AUTOSAR XML (schema 3.1.2)
package /Components/SWC_InMdlT
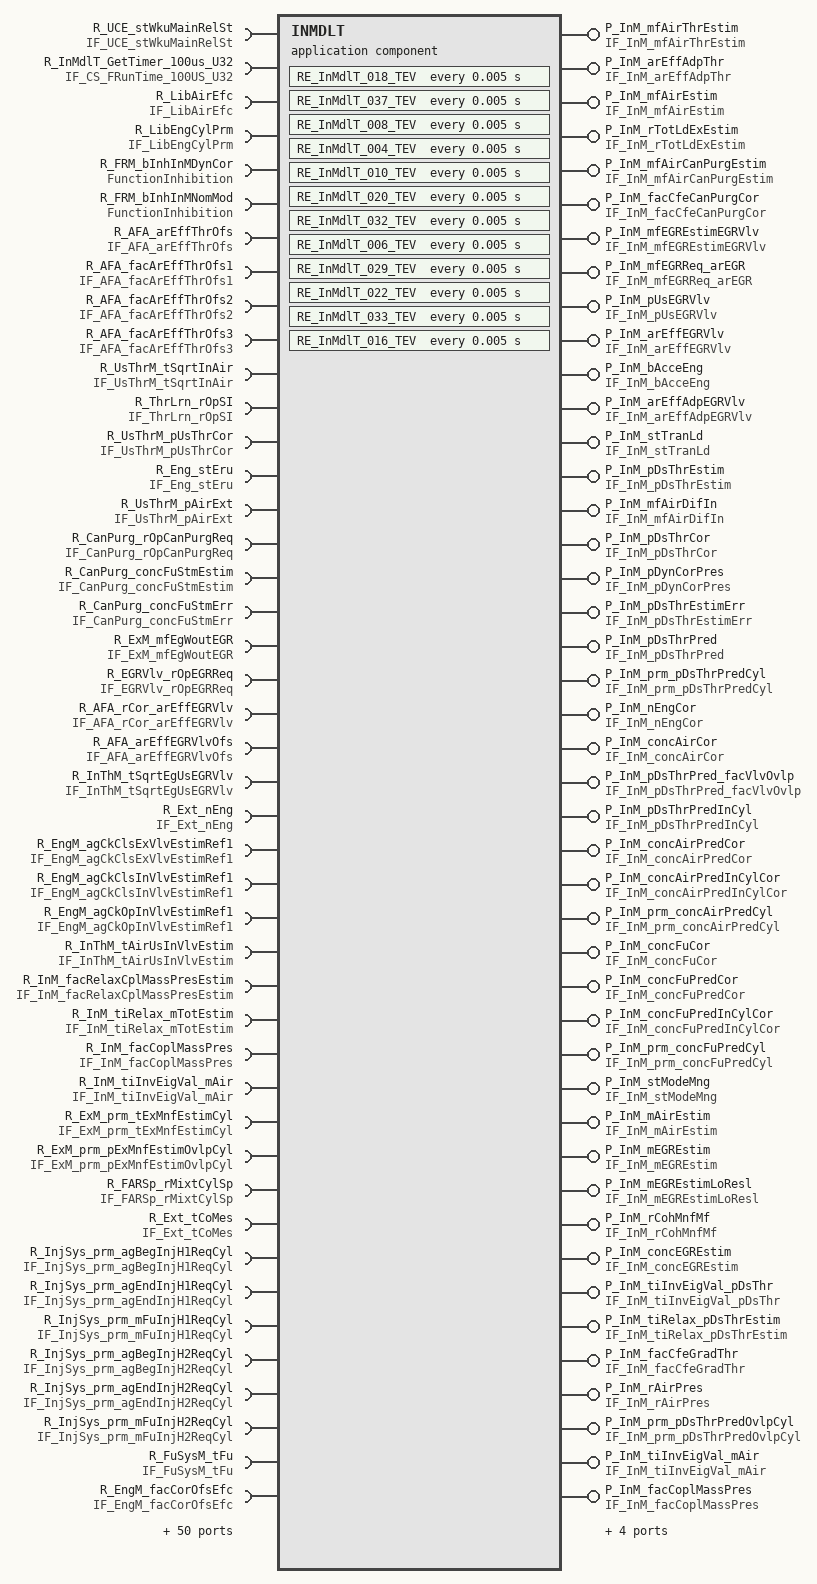
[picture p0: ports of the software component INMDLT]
  application software component type INMDLT  # InMdlT
    6 x require port:
      R_UCE_stWkuMainRelSt: required-interface=IF_UCE_stWkuMainRelSt
      R_InMdlT_GetTimer_100us_U32: required-interface=IF_CS_FRunTime_100US_U32
      R_LibAirEfc: required-interface=IF_LibAirEfc
      R_LibEngCylPrm: required-interface=IF_LibEngCylPrm
      R_FRM_bInhInMDynCor: required-interface=FunctionInhibition
      R_FRM_bInhInMNomMod: required-interface=FunctionInhibition
    48 x provide port:
      P_InM_mfAirThrEstim: unqueued-sender-com-spec{data-element=InM_mfAirThrEstim, can-invalidate=false, init-value=ConstantValue}, provided-interface=IF_InM_mfAirThrEstim
      P_InM_arEffAdpThr: unqueued-sender-com-spec{data-element=InM_arEffAdpThr, can-invalidate=false, init-value=ConstantValue1}, provided-interface=IF_InM_arEffAdpThr
      P_InM_mfAirEstim: unqueued-sender-com-spec{data-element=InM_mfAirEstim, can-invalidate=false, init-value=UInt16InitValue}, provided-interface=IF_InM_mfAirEstim
      P_InM_rTotLdExEstim: unqueued-sender-com-spec{data-element=InM_rTotLdExEstim, can-invalidate=false, init-value=UInt16InitValue3}, provided-interface=IF_InM_rTotLdExEstim
      P_InM_mfAirCanPurgEstim: unqueued-sender-com-spec{data-element=InM_mfAirCanPurgEstim, can-invalidate=false, init-value=ConstantValue5}, provided-interface=IF_InM_mfAirCanPurgEstim
      P_InM_facCfeCanPurgCor: unqueued-sender-com-spec{data-element=InM_facCfeCanPurgCor, can-invalidate=false, init-value=UInt8InitValue}, provided-interface=IF_InM_facCfeCanPurgCor
      P_InM_mfEGREstimEGRVlv: unqueued-sender-com-spec{data-element=InM_mfEGREstimEGRVlv, can-invalidate=false, init-value=ConstantValue7}, provided-interface=IF_InM_mfEGREstimEGRVlv
      P_InM_mfEGRReq_arEGR: unqueued-sender-com-spec{data-element=InM_mfEGRReq_arEGR, can-invalidate=false, init-value=UInt16InitValue9}, provided-interface=IF_InM_mfEGRReq_arEGR
      P_InM_pUsEGRVlv: unqueued-sender-com-spec{data-element=InM_pUsEGRVlv, can-invalidate=false, init-value=UInt16InitValue11}, provided-interface=IF_InM_pUsEGRVlv
      P_InM_arEffEGRVlv: unqueued-sender-com-spec{data-element=InM_arEffEGRVlv, can-invalidate=false, init-value=ConstantValue13}, provided-interface=IF_InM_arEffEGRVlv
      P_InM_bAcceEng: unqueued-sender-com-spec{data-element=InM_bAcceEng, can-invalidate=false, init-value=BooleanInitValue}, provided-interface=IF_InM_bAcceEng
      P_InM_arEffAdpEGRVlv: unqueued-sender-com-spec{data-element=InM_arEffAdpEGRVlv, can-invalidate=false, init-value=ConstantValue15}, provided-interface=IF_InM_arEffAdpEGRVlv
      P_InM_stTranLd: unqueued-sender-com-spec{data-element=InM_stTranLd, can-invalidate=false, init-value=UInt8InitValue17}, provided-interface=IF_InM_stTranLd
      P_InM_pDsThrEstim: unqueued-sender-com-spec{data-element=InM_pDsThrEstim, can-invalidate=false, init-value=ConstantValue19}, provided-interface=IF_InM_pDsThrEstim
      P_InM_mfAirDifIn: unqueued-sender-com-spec{data-element=InM_mfAirDifIn, can-invalidate=false, init-value=SInt16InitValue}, provided-interface=IF_InM_mfAirDifIn
      P_InM_pDsThrCor: unqueued-sender-com-spec{data-element=InM_pDsThrCor, can-invalidate=false, init-value=ConstantValue21}, provided-interface=IF_InM_pDsThrCor
      P_InM_pDynCorPres: unqueued-sender-com-spec{data-element=InM_pDynCorPres, can-invalidate=false, init-value=ConstantValue23}, provided-interface=IF_InM_pDynCorPres
      P_InM_pDsThrEstimErr: unqueued-sender-com-spec{data-element=InM_pDsThrEstimErr, can-invalidate=false, init-value=ConstantValue25}, provided-interface=IF_InM_pDsThrEstimErr
      P_InM_pDsThrPred: unqueued-sender-com-spec{data-element=InM_pDsThrPred, can-invalidate=false, init-value=ConstantValue27}, provided-interface=IF_InM_pDsThrPred
      P_InM_prm_pDsThrPredCyl: unqueued-sender-com-spec{data-element=InM_prm_pDsThrPredCyl, can-invalidate=false, init-value=ArrayConstantValue}, provided-interface=IF_InM_prm_pDsThrPredCyl
      P_InM_nEngCor: unqueued-sender-com-spec{data-element=InM_nEngCor, can-invalidate=false, init-value=UInt16InitValue29}, provided-interface=IF_InM_nEngCor
      P_InM_concAirCor: unqueued-sender-com-spec{data-element=InM_concAirCor, can-invalidate=false, init-value=ConstantValue31}, provided-interface=IF_InM_concAirCor
      P_InM_pDsThrPred_facVlvOvlp: unqueued-sender-com-spec{data-element=InM_pDsThrPred_facVlvOvlp, can-invalidate=false, init-value=ConstantValue33}, provided-interface=IF_InM_pDsThrPred_facVlvOvlp
      P_InM_pDsThrPredInCyl: unqueued-sender-com-spec{data-element=InM_pDsThrPredInCyl, can-invalidate=false, init-value=UInt16InitValue35}, provided-interface=IF_InM_pDsThrPredInCyl
      P_InM_concAirPredCor: unqueued-sender-com-spec{data-element=InM_concAirPredCor, can-invalidate=false, init-value=UInt16InitValue37}, provided-interface=IF_InM_concAirPredCor
      P_InM_concAirPredInCylCor: unqueued-sender-com-spec{data-element=InM_concAirPredInCylCor, can-invalidate=false, init-value=UInt16InitValue39}, provided-interface=IF_InM_concAirPredInCylCor
      P_InM_prm_concAirPredCyl: unqueued-sender-com-spec{data-element=InM_prm_concAirPredCyl, can-invalidate=false, init-value=ArrayConstantValue41}, provided-interface=IF_InM_prm_concAirPredCyl
      P_InM_concFuCor: unqueued-sender-com-spec{data-element=InM_concFuCor, can-invalidate=false, init-value=UInt16InitValue43}, provided-interface=IF_InM_concFuCor
      P_InM_concFuPredCor: unqueued-sender-com-spec{data-element=InM_concFuPredCor, can-invalidate=false, init-value=UInt16InitValue45}, provided-interface=IF_InM_concFuPredCor
      P_InM_concFuPredInCylCor: unqueued-sender-com-spec{data-element=InM_concFuPredInCylCor, can-invalidate=false, init-value=UInt16InitValue47}, provided-interface=IF_InM_concFuPredInCylCor
      P_InM_prm_concFuPredCyl: unqueued-sender-com-spec{data-element=InM_prm_concFuPredCyl, can-invalidate=false, init-value=rt_Array_UInt16_6InitValue}, provided-interface=IF_InM_prm_concFuPredCyl
      P_InM_stModeMng: unqueued-sender-com-spec{data-element=InM_stModeMng, can-invalidate=false, init-value=UInt8InitValue49}, provided-interface=IF_InM_stModeMng
      P_InM_mAirEstim: unqueued-sender-com-spec{data-element=InM_mAirEstim, can-invalidate=false, init-value=UInt32InitValue}, provided-interface=IF_InM_mAirEstim
      P_InM_mEGREstim: unqueued-sender-com-spec{data-element=InM_mEGREstim, can-invalidate=false, init-value=ConstantValue51}, provided-interface=IF_InM_mEGREstim
      P_InM_mEGREstimLoResl: unqueued-sender-com-spec{data-element=InM_mEGREstimLoResl, can-invalidate=false, init-value=UInt16InitValue53}, provided-interface=IF_InM_mEGREstimLoResl
      P_InM_rCohMnfMf: unqueued-sender-com-spec{data-element=InM_rCohMnfMf, can-invalidate=false, init-value=UInt16InitValue55}, provided-interface=IF_InM_rCohMnfMf
      P_InM_concEGREstim: unqueued-sender-com-spec{data-element=InM_concEGREstim, can-invalidate=false, init-value=ConstantValue57}, provided-interface=IF_InM_concEGREstim
      P_InM_tiInvEigVal_pDsThr: unqueued-sender-com-spec{data-element=InM_tiInvEigVal_pDsThr, can-invalidate=false, init-value=UInt16InitValue59}, provided-interface=IF_InM_tiInvEigVal_pDsThr
      P_InM_tiRelax_pDsThrEstim: unqueued-sender-com-spec{data-element=InM_tiRelax_pDsThrEstim, can-invalidate=false, init-value=UInt8InitValue61}, provided-interface=IF_InM_tiRelax_pDsThrEstim
      P_InM_facCfeGradThr: unqueued-sender-com-spec{data-element=InM_facCfeGradThr, can-invalidate=false, init-value=UInt16InitValue63}, provided-interface=IF_InM_facCfeGradThr
      P_InM_rAirPres: unqueued-sender-com-spec{data-element=InM_rAirPres, can-invalidate=false, init-value=ConstantValue65}, provided-interface=IF_InM_rAirPres
      P_InM_prm_pDsThrPredOvlpCyl: unqueued-sender-com-spec{data-element=InM_prm_pDsThrPredOvlpCyl, can-invalidate=false, init-value=ArrayConstantValue67}, provided-interface=IF_InM_prm_pDsThrPredOvlpCyl
      P_InM_tiInvEigVal_mAir: unqueued-sender-com-spec{data-element=InM_tiInvEigVal_mAir, can-invalidate=false, init-value=UInt16InitValue69}, provided-interface=IF_InM_tiInvEigVal_mAir
      P_InM_facCoplMassPres: unqueued-sender-com-spec{data-element=InM_facCoplMassPres, can-invalidate=false, init-value=UInt16InitValue71}, provided-interface=IF_InM_facCoplMassPres
      P_InM_tiRelax_mTotEstim: unqueued-sender-com-spec{data-element=InM_tiRelax_mTotEstim, can-invalidate=false, init-value=UInt8InitValue73}, provided-interface=IF_InM_tiRelax_mTotEstim
      P_InM_facRelaxCplMassPresEstim: unqueued-sender-com-spec{data-element=InM_facRelaxCplMassPresEstim, can-invalidate=false, init-value=UInt16InitValue75}, provided-interface=IF_InM_facRelaxCplMassPresEstim
      P_InM_mfTotCanPurgEstim: unqueued-sender-com-spec{data-element=InM_mfTotCanPurgEstim, can-invalidate=false, init-value=UInt16InitValue77}, provided-interface=IF_InM_mfTotCanPurgEstim
      P_InM_pBackEgPUsEGRVlv: unqueued-sender-com-spec{data-element=InM_pBackEgPUsEGRVlv, can-invalidate=false, init-value=UInt16InitValue79}, provided-interface=IF_InM_pBackEgPUsEGRVlv
    88 x require port:
      R_AFA_arEffThrOfs: unqueued-receiver-com-spec{data-element=AFA_arEffThrOfs, init-value=ConstantValue81, resync-time=0}, required-interface=IF_AFA_arEffThrOfs
      R_AFA_facArEffThrOfs1: unqueued-receiver-com-spec{data-element=AFA_facArEffThrOfs1, init-value=ConstantValue83, resync-time=0}, required-interface=IF_AFA_facArEffThrOfs1
      R_AFA_facArEffThrOfs2: unqueued-receiver-com-spec{data-element=AFA_facArEffThrOfs2, init-value=ConstantValue85, resync-time=0}, required-interface=IF_AFA_facArEffThrOfs2
      R_AFA_facArEffThrOfs3: unqueued-receiver-com-spec{data-element=AFA_facArEffThrOfs3, init-value=ConstantValue87, resync-time=0}, required-interface=IF_AFA_facArEffThrOfs3
      R_UsThrM_tSqrtInAir: unqueued-receiver-com-spec{data-element=UsThrM_tSqrtInAir, init-value=ConstantValue89, resync-time=0}, required-interface=IF_UsThrM_tSqrtInAir
      R_ThrLrn_rOpSI: unqueued-receiver-com-spec{data-element=ThrLrn_rOpSI, init-value=ConstantValue91, resync-time=0}, required-interface=IF_ThrLrn_rOpSI
      R_UsThrM_pUsThrCor: unqueued-receiver-com-spec{data-element=UsThrM_pUsThrCor, init-value=ConstantValue93, resync-time=0}, required-interface=IF_UsThrM_pUsThrCor
      R_Eng_stEru: unqueued-receiver-com-spec{data-element=Eng_stEru, init-value=ConstantValue95, resync-time=0}, required-interface=IF_Eng_stEru
      R_UsThrM_pAirExt: unqueued-receiver-com-spec{data-element=UsThrM_pAirExt, init-value=ConstantValue97, resync-time=0}, required-interface=IF_UsThrM_pAirExt
      R_CanPurg_rOpCanPurgReq: unqueued-receiver-com-spec{data-element=CanPurg_rOpCanPurgReq, init-value=UInt8InitValue99, resync-time=0}, required-interface=IF_CanPurg_rOpCanPurgReq
      R_CanPurg_concFuStmEstim: unqueued-receiver-com-spec{data-element=CanPurg_concFuStmEstim, init-value=ConstantValue101, resync-time=0}, required-interface=IF_CanPurg_concFuStmEstim
      R_CanPurg_concFuStmErr: unqueued-receiver-com-spec{data-element=CanPurg_concFuStmErr, init-value=ConstantValue103, resync-time=0}, required-interface=IF_CanPurg_concFuStmErr
      R_ExM_mfEgWoutEGR: unqueued-receiver-com-spec{data-element=ExM_mfEgWoutEGR, init-value=ConstantValue105, resync-time=0}, required-interface=IF_ExM_mfEgWoutEGR
      R_EGRVlv_rOpEGRReq: unqueued-receiver-com-spec{data-element=EGRVlv_rOpEGRReq, init-value=UInt8InitValue107, resync-time=0}, required-interface=IF_EGRVlv_rOpEGRReq
      R_AFA_rCor_arEffEGRVlv: unqueued-receiver-com-spec{data-element=AFA_rCor_arEffEGRVlv, init-value=ConstantValue109, resync-time=0}, required-interface=IF_AFA_rCor_arEffEGRVlv
      R_AFA_arEffEGRVlvOfs: unqueued-receiver-com-spec{data-element=AFA_arEffEGRVlvOfs, init-value=ConstantValue111, resync-time=0}, required-interface=IF_AFA_arEffEGRVlvOfs
      R_InThM_tSqrtEgUsEGRVlv: unqueued-receiver-com-spec{data-element=InThM_tSqrtEgUsEGRVlv, init-value=UInt8InitValue113, resync-time=0}, required-interface=IF_InThM_tSqrtEgUsEGRVlv
      R_Ext_nEng: unqueued-receiver-com-spec{data-element=Ext_nEng, init-value=ConstantValue115, resync-time=0}, required-interface=IF_Ext_nEng
      R_EngM_agCkClsExVlvEstimRef1: unqueued-receiver-com-spec{data-element=EngM_agCkClsExVlvEstimRef1, init-value=ConstantValue117, resync-time=0}, required-interface=IF_EngM_agCkClsExVlvEstimRef1
      R_EngM_agCkClsInVlvEstimRef1: unqueued-receiver-com-spec{data-element=EngM_agCkClsInVlvEstimRef1, init-value=ConstantValue119, resync-time=0}, required-interface=IF_EngM_agCkClsInVlvEstimRef1
      R_EngM_agCkOpInVlvEstimRef1: unqueued-receiver-com-spec{data-element=EngM_agCkOpInVlvEstimRef1, init-value=ConstantValue121, resync-time=0}, required-interface=IF_EngM_agCkOpInVlvEstimRef1
      R_InThM_tAirUsInVlvEstim: unqueued-receiver-com-spec{data-element=InThM_tAirUsInVlvEstim, init-value=ConstantValue123, resync-time=0}, required-interface=IF_InThM_tAirUsInVlvEstim
      R_InM_facRelaxCplMassPresEstim: unqueued-receiver-com-spec{data-element=InM_facRelaxCplMassPresEstim, init-value=UInt16InitValue125, resync-time=0}, required-interface=IF_InM_facRelaxCplMassPresEstim
      R_InM_tiRelax_mTotEstim: unqueued-receiver-com-spec{data-element=InM_tiRelax_mTotEstim, init-value=UInt8InitValue127, resync-time=0}, required-interface=IF_InM_tiRelax_mTotEstim
      R_InM_facCoplMassPres: unqueued-receiver-com-spec{data-element=InM_facCoplMassPres, init-value=UInt16InitValue129, resync-time=0}, required-interface=IF_InM_facCoplMassPres
      R_InM_tiInvEigVal_mAir: unqueued-receiver-com-spec{data-element=InM_tiInvEigVal_mAir, init-value=UInt16InitValue131, resync-time=0}, required-interface=IF_InM_tiInvEigVal_mAir
      R_ExM_prm_tExMnfEstimCyl: unqueued-receiver-com-spec{data-element=ExM_prm_tExMnfEstimCyl, init-value=ArrayConstantValue133, resync-time=0}, required-interface=IF_ExM_prm_tExMnfEstimCyl
      R_ExM_prm_pExMnfEstimOvlpCyl: unqueued-receiver-com-spec{data-element=ExM_prm_pExMnfEstimOvlpCyl, init-value=ArrayConstantValue135, resync-time=0}, required-interface=IF_ExM_prm_pExMnfEstimOvlpCyl
      R_FARSp_rMixtCylSp: unqueued-receiver-com-spec{data-element=FARSp_rMixtCylSp, init-value=ConstantValue137, resync-time=0}, required-interface=IF_FARSp_rMixtCylSp
      R_Ext_tCoMes: unqueued-receiver-com-spec{data-element=Ext_tCoMes, init-value=ConstantValue139, resync-time=0}, required-interface=IF_Ext_tCoMes
      R_InjSys_prm_agBegInjH1ReqCyl: unqueued-receiver-com-spec{data-element=InjSys_prm_agBegInjH1ReqCyl, init-value=ArrayConstantValue141, resync-time=0}, required-interface=IF_InjSys_prm_agBegInjH1ReqCyl
      R_InjSys_prm_agEndInjH1ReqCyl: unqueued-receiver-com-spec{data-element=InjSys_prm_agEndInjH1ReqCyl, init-value=ArrayConstantValue143, resync-time=0}, required-interface=IF_InjSys_prm_agEndInjH1ReqCyl
      R_InjSys_prm_mFuInjH1ReqCyl: unqueued-receiver-com-spec{data-element=InjSys_prm_mFuInjH1ReqCyl, init-value=ArrayConstantValue145, resync-time=0}, required-interface=IF_InjSys_prm_mFuInjH1ReqCyl
      R_InjSys_prm_agBegInjH2ReqCyl: unqueued-receiver-com-spec{data-element=InjSys_prm_agBegInjH2ReqCyl, init-value=ArrayConstantValue147, resync-time=0}, required-interface=IF_InjSys_prm_agBegInjH2ReqCyl
      R_InjSys_prm_agEndInjH2ReqCyl: unqueued-receiver-com-spec{data-element=InjSys_prm_agEndInjH2ReqCyl, init-value=ArrayConstantValue149, resync-time=0}, required-interface=IF_InjSys_prm_agEndInjH2ReqCyl
      R_InjSys_prm_mFuInjH2ReqCyl: unqueued-receiver-com-spec{data-element=InjSys_prm_mFuInjH2ReqCyl, init-value=ArrayConstantValue151, resync-time=0}, required-interface=IF_InjSys_prm_mFuInjH2ReqCyl
      R_FuSysM_tFu: unqueued-receiver-com-spec{data-element=FuSysM_tFu, init-value=ConstantValue153, resync-time=0}, required-interface=IF_FuSysM_tFu
      R_EngM_facCorOfsEfc: unqueued-receiver-com-spec{data-element=EngM_facCorOfsEfc, init-value=ConstantValue155, resync-time=0}, required-interface=IF_EngM_facCorOfsEfc
      R_EngM_facCorSlopEfc: unqueued-receiver-com-spec{data-element=EngM_facCorSlopEfc, init-value=ConstantValue157, resync-time=0}, required-interface=IF_EngM_facCorSlopEfc
      R_UsThrM_tThrMes: unqueued-receiver-com-spec{data-element=UsThrM_tThrMes, init-value=ConstantValue159, resync-time=0}, required-interface=IF_UsThrM_tThrMes
      R_UsThrM_pDsThrMesCor: unqueued-receiver-com-spec{data-element=UsThrM_pDsThrMesCor, init-value=UInt16InitValue161, resync-time=0}, required-interface=IF_UsThrM_pDsThrMesCor
      R_InThM_tWallInMnf: unqueued-receiver-com-spec{data-element=InThM_tWallInMnf, init-value=UInt16InitValue163, resync-time=0}, required-interface=IF_InThM_tWallInMnf
      R_InThM_tMixtInMnf: unqueued-receiver-com-spec{data-element=InThM_tMixtInMnf, init-value=UInt16InitValue165, resync-time=0}, required-interface=IF_InThM_tMixtInMnf
      R_InThM_tInMnfEstim: unqueued-receiver-com-spec{data-element=InThM_tInMnfEstim, init-value=UInt16InitValue167, resync-time=0}, required-interface=IF_InThM_tInMnfEstim
      R_InThM_tEGRInMnf: unqueued-receiver-com-spec{data-element=InThM_tEGRInMnf, init-value=UInt16InitValue169, resync-time=0}, required-interface=IF_InThM_tEGRInMnf
      R_InThM_facHeatExcWallInMnf: unqueued-receiver-com-spec{data-element=InThM_facHeatExcWallInMnf, init-value=UInt8InitValue171, resync-time=0}, required-interface=IF_InThM_facHeatExcWallInMnf
      R_EGRVlv_bClnEGRFoul: unqueued-receiver-com-spec{data-element=EGRVlv_bClnEGRFoul, init-value=BooleanInitValue173, resync-time=0}, required-interface=IF_EGRVlv_bClnEGRFoul
      R_Ext_tiHldPerEng: unqueued-receiver-com-spec{data-element=Ext_tiHldPerEng, init-value=UInt16InitValue175, resync-time=0}, required-interface=IF_Ext_tiHldPerEng
      R_Eng_noExCyl: unqueued-receiver-com-spec{data-element=Eng_noExCyl, init-value=ConstantValue177, resync-time=0}, required-interface=IF_Eng_noExCyl
      R_Ext_agCkPosnCurRef2: unqueued-receiver-com-spec{data-element=Ext_agCkPosnCurRef2, init-value=UInt16InitValue179, resync-time=0}, required-interface=IF_Ext_agCkPosnCurRef2
      R_Ext_agCkOpInVlvEstimRef0: unqueued-receiver-com-spec{data-element=Ext_agCkOpInVlvEstimRef0, init-value=ConstantValue181, resync-time=0}, required-interface=IF_Ext_agCkOpInVlvEstimRef0
      R_Ext_agCkClsExVlvEstimRef0: unqueued-receiver-com-spec{data-element=Ext_agCkClsExVlvEstimRef0, init-value=ConstantValue183, resync-time=0}, required-interface=IF_Ext_agCkClsExVlvEstimRef0
      R_Eng_noExNxtCyl: unqueued-receiver-com-spec{data-element=Eng_noExNxtCyl, init-value=ConstantValue185, resync-time=0}, required-interface=IF_Eng_noExNxtCyl
      R_CanPurg_bAcvClsPurgReq: unqueued-receiver-com-spec{data-element=CanPurg_bAcvClsPurgReq, init-value=BooleanInitValue187, resync-time=0}, required-interface=IF_CanPurg_bAcvClsPurgReq
      R_EGRVlv_bAcvClsEGRReq: unqueued-receiver-com-spec{data-element=EGRVlv_bAcvClsEGRReq, init-value=BooleanInitValue189, resync-time=0}, required-interface=IF_EGRVlv_bAcvClsEGRReq
      R_EngM_mfTotExCor: unqueued-receiver-com-spec{data-element=EngM_mfTotExCor, init-value=ConstantValue191, resync-time=0}, required-interface=IF_EngM_mfTotExCor
      R_InM_mfAirCanPurgEstim: unqueued-receiver-com-spec{data-element=InM_mfAirCanPurgEstim, init-value=ConstantValue193, resync-time=0}, required-interface=IF_InM_mfAirCanPurgEstim
      R_InM_mfAirEstim: unqueued-receiver-com-spec{data-element=InM_mfAirEstim, init-value=UInt16InitValue, resync-time=0}, required-interface=IF_InM_mfAirEstim
      R_InM_mfAirThrEstim: unqueued-receiver-com-spec{data-element=InM_mfAirThrEstim, init-value=ConstantValue, resync-time=0}, required-interface=IF_InM_mfAirThrEstim
      R_InM_tiInvEigVal_pDsThr: unqueued-receiver-com-spec{data-element=InM_tiInvEigVal_pDsThr, init-value=UInt16InitValue195, resync-time=0}, required-interface=IF_InM_tiInvEigVal_pDsThr
      R_InM_arEffAdpThr: unqueued-receiver-com-spec{data-element=InM_arEffAdpThr, init-value=ConstantValue197, resync-time=0}, required-interface=IF_InM_arEffAdpThr
      R_InM_bAcceEng: unqueued-receiver-com-spec{data-element=InM_bAcceEng, init-value=BooleanInitValue, resync-time=0}, required-interface=IF_InM_bAcceEng
      R_InM_mfEGREstimEGRVlv: unqueued-receiver-com-spec{data-element=InM_mfEGREstimEGRVlv, init-value=ConstantValue199, resync-time=0}, required-interface=IF_InM_mfEGREstimEGRVlv
      R_InM_mAirEstim: unqueued-receiver-com-spec{data-element=InM_mAirEstim, init-value=UInt32InitValue, resync-time=0}, required-interface=IF_InM_mAirEstim
      R_InM_concEGREstim: unqueued-receiver-com-spec{data-element=InM_concEGREstim, init-value=ConstantValue201, resync-time=0}, required-interface=IF_InM_concEGREstim
      R_InM_pDsThrEstim: unqueued-receiver-com-spec{data-element=InM_pDsThrEstim, init-value=ConstantValue203, resync-time=0}, required-interface=IF_InM_pDsThrEstim
      R_InM_mEGREstim: unqueued-receiver-com-spec{data-element=InM_mEGREstim, init-value=ConstantValue205, resync-time=0}, required-interface=IF_InM_mEGREstim
      R_InM_facCfeGradThr: unqueued-receiver-com-spec{data-element=InM_facCfeGradThr, init-value=UInt16InitValue207, resync-time=0}, required-interface=IF_InM_facCfeGradThr
      R_EcuM_CurrentMode: required-interface=EcuM_CurrentMode
      R_Eng_noInCyl: unqueued-receiver-com-spec{data-element=Eng_noInCyl, init-value=ConstantValue209, resync-time=0}, required-interface=IF_Eng_noInCyl
      R_EV_InMdlT_013_DRE: unqueued-receiver-com-spec{data-element=EV_InMdlT_013_DRE, init-value=UInt8InitValue211, resync-time=0}, required-interface=IF_EV_InMdlT_013_DRE
      R_EV_InMdlT_015_DRE: unqueued-receiver-com-spec{data-element=EV_InMdlT_015_DRE, init-value=UInt8InitValue213, resync-time=0}, required-interface=IF_EV_InMdlT_015_DRE
      R_EV_InMdlT_024_DRE: unqueued-receiver-com-spec{data-element=EV_InMdlT_024_DRE, init-value=UInt8InitValue215, resync-time=0}, required-interface=IF_EV_InMdlT_024_DRE
      R_InM_prm_pDsThrPredCyl: unqueued-receiver-com-spec{data-element=InM_prm_pDsThrPredCyl, init-value=ArrayConstantValue, resync-time=0}, required-interface=IF_InM_prm_pDsThrPredCyl
      R_InM_prm_concFuPredCyl: unqueued-receiver-com-spec{data-element=InM_prm_concFuPredCyl, init-value=rt_Array_UInt16_6InitValue, resync-time=0}, required-interface=IF_InM_prm_concFuPredCyl
      R_InM_prm_concAirPredCyl: unqueued-receiver-com-spec{data-element=InM_prm_concAirPredCyl, init-value=ArrayConstantValue217, resync-time=0}, required-interface=IF_InM_prm_concAirPredCyl
      R_InM_pDsThrEstimErr: unqueued-receiver-com-spec{data-element=InM_pDsThrEstimErr, init-value=ConstantValue219, resync-time=0}, required-interface=IF_InM_pDsThrEstimErr
      R_InM_pDsThrCor: unqueued-receiver-com-spec{data-element=InM_pDsThrCor, init-value=ConstantValue221, resync-time=0}, required-interface=IF_InM_pDsThrCor
      R_InM_mEGREstimLoResl: unqueued-receiver-com-spec{data-element=InM_mEGREstimLoResl, init-value=UInt16InitValue223, resync-time=0}, required-interface=IF_InM_mEGREstimLoResl
      R_InM_rCohMnfMf: unqueued-receiver-com-spec{data-element=InM_rCohMnfMf, init-value=UInt16InitValue225, resync-time=0}, required-interface=IF_InM_rCohMnfMf
      R_InM_rAirPres: unqueued-receiver-com-spec{data-element=InM_rAirPres, init-value=ConstantValue227, resync-time=0}, required-interface=IF_InM_rAirPres
      R_InM_prm_pDsThrPredOvlpCyl: unqueued-receiver-com-spec{data-element=InM_prm_pDsThrPredOvlpCyl, init-value=ArrayConstantValue229, resync-time=0}, required-interface=IF_InM_prm_pDsThrPredOvlpCyl
      R_InM_tiRelax_pDsThrEstim: unqueued-receiver-com-spec{data-element=InM_tiRelax_pDsThrEstim, init-value=UInt8InitValue231, resync-time=0}, required-interface=IF_InM_tiRelax_pDsThrEstim
      R_InM_mfTotCanPurgEstim: unqueued-receiver-com-spec{data-element=InM_mfTotCanPurgEstim, init-value=UInt16InitValue233, resync-time=0}, required-interface=IF_InM_mfTotCanPurgEstim
      R_InM_pBackEgPUsEGRVlv: unqueued-receiver-com-spec{data-element=InM_pBackEgPUsEGRVlv, init-value=UInt16InitValue235, resync-time=0}, required-interface=IF_InM_pBackEgPUsEGRVlv
      R_InThM_nEngCor: unqueued-receiver-com-spec{data-element=InThM_nEngCor, init-value=ConstantValue237, resync-time=0}, required-interface=IF_InThM_nEngCor
      R_Blby_mfFuStmCmpAirSys: unqueued-receiver-com-spec{data-element=Blby_mfFuStmCmpAirSys, init-value=ConstantValue239, resync-time=0}, required-interface=IF_Blby_mfFuStmCmpAirSys
      R_Eng_tOilEstim: unqueued-receiver-com-spec{data-element=Eng_tOilEstim, init-value=SInt16InitValue241, resync-time=0}, required-interface=IF_Eng_tOilEstim
  172 x constant specification:
    ArrayConstantValue
      value:
        array specification ArrayConstantValue: type=rt_Array_UInt16_6_m9
          6 x integer literal, all with type=DT_InM_prm_pDsThrPredCyl, value=0:
            Const
            Const{1..5}
    ArrayConstantValue133
      value:
        array specification ArrayConstantValue133: type=rt_Array_UInt16_6_m1
          6 x integer literal, all with type=DT_ExM_prm_tExMnfEstimCyl, value=0:
            Const
            Const{1..5}
    ArrayConstantValue135
      value:
        array specification ArrayConstantValue135: type=rt_Array_UInt16_6_m2
          6 x integer literal, all with type=DT_ExM_prm_pExMnfEstimOvlpCyl, value=0:
            Const
            Const{1..5}
    ArrayConstantValue141
      value:
        array specification ArrayConstantValue141: type=rt_Array_UInt16_6_m3
          6 x integer literal, all with type=DT_InjSys_prm_agBegInjH1ReqCyl, value=0:
            Const
            Const{1..5}
    ArrayConstantValue143
      value:
        array specification ArrayConstantValue143: type=rt_Array_UInt16_6_m18
          6 x integer literal, all with type=DT_InjSys_prm_agEndInjH1ReqCyl, value=0:
            Const
            Const{1..5}
    ArrayConstantValue145
      value:
        array specification ArrayConstantValue145: type=rt_Array_UInt16_6_m19
          6 x integer literal, all with type=DT_InjSys_prm_mFuInjH1ReqCyl, value=0:
            Const
            Const{1..5}
    ArrayConstantValue147
      value:
        array specification ArrayConstantValue147: type=rt_Array_UInt16_6_m4
          6 x integer literal, all with type=DT_InjSys_prm_agBegInjH2ReqCyl, value=0:
            Const
            Const{1..5}
    ArrayConstantValue149
      value:
        array specification ArrayConstantValue149: type=rt_Array_UInt16_6_m20
          6 x integer literal, all with type=DT_InjSys_prm_agEndInjH2ReqCyl, value=0:
            Const
            Const{1..5}
    ArrayConstantValue151
      value:
        array specification ArrayConstantValue151: type=rt_Array_UInt16_6_m5
          6 x integer literal, all with type=DT_InjSys_prm_mFuInjH2ReqCyl, value=0:
            Const
            Const{1..5}
    ArrayConstantValue217
      value:
        array specification ArrayConstantValue217: type=rt_Array_UInt16_6_m0
          6 x integer literal, all with type=DT_InM_prm_concAirPredCyl, value=1:
            Const
            Const{1..5}
    ArrayConstantValue229
      value:
        array specification ArrayConstantValue229: type=rt_Array_UInt16_6_m17
          6 x integer literal, all with type=DT_InM_prm_pDsThrPredOvlpCyl, value=0:
            Const
            Const{1..5}
    ArrayConstantValue41
      value:
        array specification ArrayConstantValue41: type=rt_Array_UInt16_6_m0
          6 x integer literal, all with type=DT_InM_prm_concAirPredCyl, value=1:
            Const
            Const{1..5}
    ArrayConstantValue67
      value:
        array specification ArrayConstantValue67: type=rt_Array_UInt16_6_m17
          6 x integer literal, all with type=DT_InM_prm_pDsThrPredOvlpCyl, value=0:
            Const
            Const{1..5}
    BooleanInitValue
      value:
        boolean literal BooleanInitValue: type=DT_InM_bAcceEng, value=false
    BooleanInitValue173
      value:
        boolean literal BooleanInitValue173: type=DT_EGRVlv_bClnEGRFoul, value=false
    BooleanInitValue187
      value:
        boolean literal BooleanInitValue187: type=DT_CanPurg_bAcvClsPurgReq, value=false
    BooleanInitValue189
      value:
        boolean literal BooleanInitValue189: type=DT_EGRVlv_bAcvClsEGRReq, value=true
    ConstantValue
      value:
        integer literal ConstantValue: type=DT_InM_mfAirThrEstim, value=0
    ConstantValue1
      value:
        integer literal ConstantValue1: type=DT_InM_arEffAdpThr, value=0
    ConstantValue101
      value:
        integer literal ConstantValue101: type=DT_CanPurg_concFuStmEstim, value=0
    ConstantValue103
      value:
        integer literal ConstantValue103: type=DT_CanPurg_concFuStmErr, value=0
    ConstantValue105
      value:
        integer literal ConstantValue105: type=DT_ExM_mfEgWoutEGR, value=0
    ConstantValue109
      value:
        integer literal ConstantValue109: type=DT_AFA_rCor_arEffEGRVlv, value=0
    ConstantValue111
      value:
        integer literal ConstantValue111: type=DT_AFA_arEffEGRVlvOfs, value=0
    ConstantValue115
      value:
        integer literal ConstantValue115: type=DT_Ext_nEng, value=0
    ConstantValue117
      value:
        integer literal ConstantValue117: type=DT_EngM_agCkClsExVlvEstimRef1, value=0
    ConstantValue119
      value:
        integer literal ConstantValue119: type=DT_EngM_agCkClsInVlvEstimRef1, value=0
    ConstantValue121
      value:
        integer literal ConstantValue121: type=DT_EngM_agCkOpInVlvEstimRef1, value=0
    ConstantValue123
      value:
        integer literal ConstantValue123: type=DT_InThM_tAirUsInVlvEstim, value=0
    ConstantValue13
      value:
        integer literal ConstantValue13: type=DT_InM_arEffEGRVlv, value=0
    ConstantValue137
      value:
        integer literal ConstantValue137: type=DT_FARSp_rMixtCylSp, value=4096
    ConstantValue139
      value:
        integer literal ConstantValue139: type=DT_Ext_tCoMes, value=20
    ConstantValue15
      value:
        integer literal ConstantValue15: type=DT_InM_arEffAdpEGRVlv, value=0
    ConstantValue153
      value:
        integer literal ConstantValue153: type=DT_FuSysM_tFu, value=0
    ConstantValue155
      value:
        integer literal ConstantValue155: type=DT_EngM_facCorOfsEfc, value=0
    ConstantValue157
      value:
        integer literal ConstantValue157: type=DT_EngM_facCorSlopEfc, value=32768
    ConstantValue159
      value:
        integer literal ConstantValue159: type=DT_UsThrM_tThrMes, value=0
    ConstantValue177
      value:
        integer literal ConstantValue177: type=DT_Eng_noExCyl, value=1
    ConstantValue181
      value:
        integer literal ConstantValue181: type=DT_Ext_agCkOpInVlvEstimRef0, value=-1024
    ConstantValue183
      value:
        integer literal ConstantValue183: type=DT_Ext_agCkClsExVlvEstimRef0, value=-1024
    ConstantValue185
      value:
        integer literal ConstantValue185: type=DT_Eng_noExNxtCyl, value=1
    ConstantValue19
      value:
        integer literal ConstantValue19: type=DT_InM_pDsThrEstim, value=0
    ConstantValue191
      value:
        integer literal ConstantValue191: type=DT_EngM_mfTotExCor, value=0
    ConstantValue193
      value:
        integer literal ConstantValue193: type=DT_InM_mfAirCanPurgEstim, value=0
    ConstantValue197
      value:
        integer literal ConstantValue197: type=DT_InM_arEffAdpThr, value=0
    ConstantValue199
      value:
        integer literal ConstantValue199: type=DT_InM_mfEGREstimEGRVlv, value=0
    ConstantValue201
      value:
        integer literal ConstantValue201: type=DT_InM_concEGREstim, value=0
    ConstantValue203
      value:
        integer literal ConstantValue203: type=DT_InM_pDsThrEstim, value=0
    ConstantValue205
      value:
        integer literal ConstantValue205: type=DT_InM_mEGREstim, value=0
    ConstantValue209
      value:
        integer literal ConstantValue209: type=DT_Eng_noInCyl, value=1
    ConstantValue21
      value:
        integer literal ConstantValue21: type=DT_InM_pDsThrCor, value=0
    ConstantValue219
      value:
        integer literal ConstantValue219: type=DT_InM_pDsThrEstimErr, value=0
    ConstantValue221
      value:
        integer literal ConstantValue221: type=DT_InM_pDsThrCor, value=0
    ConstantValue227
      value:
        integer literal ConstantValue227: type=DT_InM_rAirPres, value=58982
    ConstantValue23
      value:
        integer literal ConstantValue23: type=DT_InM_pDynCorPres, value=0
    ConstantValue237
      value:
        integer literal ConstantValue237: type=DT_InThM_nEngCor, value=0
    ConstantValue239
      value:
        integer literal ConstantValue239: type=DT_Blby_mfFuStmCmpAirSys, value=0
    ConstantValue25
      value:
        integer literal ConstantValue25: type=DT_InM_pDsThrEstimErr, value=0
    ConstantValue27
      value:
        integer literal ConstantValue27: type=DT_InM_pDsThrPred, value=0
    ConstantValue31
      value:
        integer literal ConstantValue31: type=DT_InM_concAirCor, value=1
    ConstantValue33
      value:
        integer literal ConstantValue33: type=DT_InM_pDsThrPred_facVlvOvlp, value=0
    ConstantValue5
      value:
        integer literal ConstantValue5: type=DT_InM_mfAirCanPurgEstim, value=0
    ConstantValue51
      value:
        integer literal ConstantValue51: type=DT_InM_mEGREstim, value=0
    ConstantValue57
      value:
        integer literal ConstantValue57: type=DT_InM_concEGREstim, value=0
    ConstantValue65
      value:
        integer literal ConstantValue65: type=DT_InM_rAirPres, value=58982
    ConstantValue7
      value:
        integer literal ConstantValue7: type=DT_InM_mfEGREstimEGRVlv, value=0
    ConstantValue81
      value:
        integer literal ConstantValue81: type=DT_AFA_arEffThrOfs, value=0
    ConstantValue83
      value:
        integer literal ConstantValue83: type=DT_AFA_facArEffThrOfs1, value=0
    ConstantValue85
      value:
        integer literal ConstantValue85: type=DT_AFA_facArEffThrOfs2, value=0
    ConstantValue87
      value:
        integer literal ConstantValue87: type=DT_AFA_facArEffThrOfs3, value=0
    ConstantValue89
      value:
        integer literal ConstantValue89: type=DT_UsThrM_tSqrtInAir, value=120
    ConstantValue91
      value:
        integer literal ConstantValue91: type=DT_ThrLrn_rOpSI, value=0
    ConstantValue93
      value:
        integer literal ConstantValue93: type=DT_UsThrM_pUsThrCor, value=0
    ConstantValue95
      value:
        integer literal ConstantValue95: type=DT_Eng_stEru, value=1
    ConstantValue97
      value:
        integer literal ConstantValue97: type=DT_UsThrM_pAirExt, value=0
    InitValue_Float32_0
      value:
        real literal InitValue_Float32_0: type=DT_InM_pPrevSenBuffer_01_irv, value=0
    InitValue_Float32_0243
      value:
        real literal InitValue_Float32_0243: type=DT_InM_mGradFuStmEstim_irv, value=0
    InitValue_Float32_0245
      value:
        real literal InitValue_Float32_0245: type=DT_InM_mfFuStmCanPurgEstim_irv, value=0
    InitValue_Float32_0247
      value:
        real literal InitValue_Float32_0247: type=DT_AirEfc_facChrExpScvFilEstim_irv, value=0
    InitValue_Float32_0249
      value:
        real literal InitValue_Float32_0249: type=DT_InM_concAirEstim_irv, value=0
    InitValue_Float32_0251
      value:
        real literal InitValue_Float32_0251: type=DT_InM_agCkClsInVlvEstimRef2_irv, value=0
    InitValue_Float32_0253
      value:
        real literal InitValue_Float32_0253: type=DT_InM_concFuPredInCyl_irv, value=0
    InitValue_Float32_0255
      value:
        real literal InitValue_Float32_0255: type=DT_InM_mFuStmEstim_irv, value=0
    InitValue_Float32_0257
      value:
        real literal InitValue_Float32_0257: type=DT_InM_pPrevSenBuffer_03_irv, value=0
    InitValue_Float32_0259
      value:
        real literal InitValue_Float32_0259: type=DT_AirEfc_facChrExpFilEstim_irv, value=0
    InitValue_Float32_0261
      value:
        real literal InitValue_Float32_0261: type=DT_InM_concAirPredInCyl_irv, value=0
    InitValue_Float32_0263
      value:
        real literal InitValue_Float32_0263: type=DT_InM_tiHrznPred_facVlvOvlp_irv, value=0
    InitValue_Float32_0265
      value:
        real literal InitValue_Float32_0265: type=DT_InM_mGradAirEstim_irv, value=0
    InitValue_Float32_0267
      value:
        real literal InitValue_Float32_0267: type=DT_InM_concAirPred_irv, value=0
    InitValue_Float32_0269
      value:
        real literal InitValue_Float32_0269: type=DT_InM_mAirEstimPrev_irv, value=0
    InitValue_Float32_0271
      value:
        real literal InitValue_Float32_0271: type=DT_InM_mEGREstimPrev_irv, value=0
    InitValue_Float32_0273
      value:
        real literal InitValue_Float32_0273: type=DT_InM_pDsThrPredInCylRaw_irv, value=0
    InitValue_Float32_0275
      value:
        real literal InitValue_Float32_0275: type=DT_InM_concFuStmEstim_irv, value=0
    InitValue_Float32_0277
      value:
        real literal InitValue_Float32_0277: type=DT_InM_mFuStmEstimPrev_irv, value=0
    InitValue_Float32_0279
      value:
        real literal InitValue_Float32_0279: type=DT_InM_mGradEGREstim_irv, value=0
    InitValue_Float32_0281
      value:
        real literal InitValue_Float32_0281: type=DT_InM_tiHrznPredInCyl_irv, value=0
    InitValue_Float32_0283
      value:
        real literal InitValue_Float32_0283: type=DT_InM_pPrevSenBuffer_02_irv, value=0
    InitValue_Float32_0285
      value:
        real literal InitValue_Float32_0285: type=DT_InM_pDsThrEstimPrev_irv, value=0
    InitValue_Float32_0287
      value:
        real literal InitValue_Float32_0287: type=DT_InM_facSlopEfcEstim_irv, value=0
    InitValue_Float32_0289
      value:
        real literal InitValue_Float32_0289: type=DT_InM_pGradDsThrEstim_irv, value=0
    InitValue_Float32_0291
      value:
        real literal InitValue_Float32_0291: type=DT_InM_pPrevSenFil_irv, value=0
    InitValue_Float32_0293
      value:
        real literal InitValue_Float32_0293: type=DT_InM_concFuPred_irv, value=0
    InitValue_Float32_0295
      value:
        real literal InitValue_Float32_0295: type=DT_InM_pPrev1SenFil_irv, value=0
    InitValue_Float32_0297
      value:
        real literal InitValue_Float32_0297: type=DT_InM_pDsThrEstimLoResl_irv, value=0
    InitValue_Float32_0299
      value:
        real literal InitValue_Float32_0299: type=DT_InM_mTotEstim_irv, value=0
    InitValue_Float32_0303
      value:
        real literal InitValue_Float32_0303: type=DT_InM_tiHrznPred_irv, value=0
    InitValue_Float32_0305
      value:
        real literal InitValue_Float32_0305: type=DT_InM_concFuStmRaw_irv, value=0
    InitValue_Float32_0307
      value:
        real literal InitValue_Float32_0307: type=DT_InM_pDsThr_facVlvOvlp_irv, value=0
    InitValue_Float32_0309
      value:
        real literal InitValue_Float32_0309: type=DT_InM_pDsThrPredRaw_irv, value=0
    InitValue_Float32_0311
      value:
        real literal InitValue_Float32_0311: type=DT_InM_pPrevSenSat_irv, value=0
    InitValue_Float32_0313
      value:
        real literal InitValue_Float32_0313: type=DT_InM_pDsThrSenEstim_irv, value=0
    InitValue_Float32_0315
      value:
        real literal InitValue_Float32_0315: type=DT_InM_pPrevSenBuffer_04_irv, value=0
    InitValue_Float32_0317
      value:
        real literal InitValue_Float32_0317: type=DT_InM_concAirRaw_irv, value=0
    InitValue_UInt16_0
      value:
        integer literal InitValue_UInt16_0: type=DT_InM_nEngPred_irv, value=0
    InitValue_UInt16_0301
      value:
        integer literal InitValue_UInt16_0301: type=DT_InM_mfTotExEstim_irv, value=0
    InitValue_UInt32_0
      value:
        integer literal InitValue_UInt32_0: type=DT_FRT_tiSenFilTmr_irv, value=0
    InitValue_UInt32_0319
      value:
        integer literal InitValue_UInt32_0319: type=DT_InM_ctEGRVlvCls_irv, value=0
    InitValue_UInt8_0
      value:
        integer literal InitValue_UInt8_0: type=DT_InM_cntPrevSenPres_irv, value=0
    rt_Array_UInt16_6InitValue
      value:
        array specification rt_Array_UInt16_6InitValue: type=rt_Array_UInt16_6_m16
          6 x integer literal, all with type=DT_InM_prm_concFuPredCyl, value=0:
            UInt16_{1..6}
    SInt16InitValue
      value:
        integer literal SInt16InitValue: type=DT_InM_mfAirDifIn, value=-32768
    SInt16InitValue241
      value:
        integer literal SInt16InitValue241: type=DT_Eng_tOilEstim, value=0
    UInt16InitValue
      value:
        integer literal UInt16InitValue: type=DT_InM_mfAirEstim, value=0
    UInt16InitValue11
      value:
        integer literal UInt16InitValue11: type=DT_InM_pUsEGRVlv, value=0
    UInt16InitValue125
      value:
        integer literal UInt16InitValue125: type=DT_InM_facRelaxCplMassPresEstim, value=0
    UInt16InitValue129
      value:
        integer literal UInt16InitValue129: type=DT_InM_facCoplMassPres, value=0
    UInt16InitValue131
      value:
        integer literal UInt16InitValue131: type=DT_InM_tiInvEigVal_mAir, value=0
    UInt16InitValue161
      value:
        integer literal UInt16InitValue161: type=DT_UsThrM_pDsThrMesCor, value=0
    UInt16InitValue163
      value:
        integer literal UInt16InitValue163: type=DT_InThM_tWallInMnf, value=0
    UInt16InitValue165
      value:
        integer literal UInt16InitValue165: type=DT_InThM_tMixtInMnf, value=0
    UInt16InitValue167
      value:
        integer literal UInt16InitValue167: type=DT_InThM_tInMnfEstim, value=0
    UInt16InitValue169
      value:
        integer literal UInt16InitValue169: type=DT_InThM_tEGRInMnf, value=0
    UInt16InitValue175
      value:
        integer literal UInt16InitValue175: type=DT_Ext_tiHldPerEng, value=65535
    UInt16InitValue179
      value:
        integer literal UInt16InitValue179: type=DT_Ext_agCkPosnCurRef2, value=0
    UInt16InitValue195
      value:
        integer literal UInt16InitValue195: type=DT_InM_tiInvEigVal_pDsThr, value=0
    UInt16InitValue207
      value:
        integer literal UInt16InitValue207: type=DT_InM_facCfeGradThr, value=65535
    UInt16InitValue223
      value:
        integer literal UInt16InitValue223: type=DT_InM_mEGREstimLoResl, value=0
    UInt16InitValue225
      value:
        integer literal UInt16InitValue225: type=DT_InM_rCohMnfMf, value=0
    UInt16InitValue233
      value:
        integer literal UInt16InitValue233: type=DT_InM_mfTotCanPurgEstim, value=0
    UInt16InitValue235
      value:
        integer literal UInt16InitValue235: type=DT_InM_pBackEgPUsEGRVlv, value=0
    UInt16InitValue29
      value:
        integer literal UInt16InitValue29: type=DT_InM_nEngCor, value=0
    UInt16InitValue3
      value:
        integer literal UInt16InitValue3: type=DT_InM_rTotLdExEstim, value=0
    UInt16InitValue35
      value:
        integer literal UInt16InitValue35: type=DT_InM_pDsThrPredInCyl, value=0
    UInt16InitValue37
      value:
        integer literal UInt16InitValue37: type=DT_InM_concAirPredCor, value=0
    UInt16InitValue39
      value:
        integer literal UInt16InitValue39: type=DT_InM_concAirPredInCylCor, value=0
    UInt16InitValue43
      value:
        integer literal UInt16InitValue43: type=DT_InM_concFuCor, value=0
    UInt16InitValue45
      value:
        integer literal UInt16InitValue45: type=DT_InM_concFuPredCor, value=0
    UInt16InitValue47
      value:
        integer literal UInt16InitValue47: type=DT_InM_concFuPredInCylCor, value=0
    UInt16InitValue53
      value:
        integer literal UInt16InitValue53: type=DT_InM_mEGREstimLoResl, value=0
    UInt16InitValue55
      value:
        integer literal UInt16InitValue55: type=DT_InM_rCohMnfMf, value=0
    UInt16InitValue59
      value:
        integer literal UInt16InitValue59: type=DT_InM_tiInvEigVal_pDsThr, value=0
    UInt16InitValue63
      value:
        integer literal UInt16InitValue63: type=DT_InM_facCfeGradThr, value=65535
    UInt16InitValue69
      value:
        integer literal UInt16InitValue69: type=DT_InM_tiInvEigVal_mAir, value=0
    UInt16InitValue71
      value:
        integer literal UInt16InitValue71: type=DT_InM_facCoplMassPres, value=0
    UInt16InitValue75
      value:
        integer literal UInt16InitValue75: type=DT_InM_facRelaxCplMassPresEstim, value=0
    UInt16InitValue77
      value:
        integer literal UInt16InitValue77: type=DT_InM_mfTotCanPurgEstim, value=0
    UInt16InitValue79
      value:
        integer literal UInt16InitValue79: type=DT_InM_pBackEgPUsEGRVlv, value=0
    UInt16InitValue9
      value:
        integer literal UInt16InitValue9: type=DT_InM_mfEGRReq_arEGR, value=0
    UInt32InitValue
      value:
        integer literal UInt32InitValue: type=DT_InM_mAirEstim, value=0
    UInt8InitValue
      value:
        integer literal UInt8InitValue: type=DT_InM_facCfeCanPurgCor, value=0
    UInt8InitValue107
      value:
        integer literal UInt8InitValue107: type=DT_EGRVlv_rOpEGRReq, value=0
    UInt8InitValue113
      value:
        integer literal UInt8InitValue113: type=DT_InThM_tSqrtEgUsEGRVlv, value=0
    UInt8InitValue127
      value:
        integer literal UInt8InitValue127: type=DT_InM_tiRelax_mTotEstim, value=0
    UInt8InitValue17
      value:
        integer literal UInt8InitValue17: type=DT_InM_stTranLd, value=1
    UInt8InitValue171
      value:
        integer literal UInt8InitValue171: type=DT_InThM_facHeatExcWallInMnf, value=0
    UInt8InitValue211
      value:
        integer literal UInt8InitValue211: type=DT_EV_InMdlT_013_DRE, value=0
    UInt8InitValue213
      value:
        integer literal UInt8InitValue213: type=DT_EV_InMdlT_015_DRE, value=0
    UInt8InitValue215
      value:
        integer literal UInt8InitValue215: type=DT_EV_InMdlT_024_DRE, value=0
    UInt8InitValue231
      value:
        integer literal UInt8InitValue231: type=DT_InM_tiRelax_pDsThrEstim, value=0
    UInt8InitValue49
      value:
        integer literal UInt8InitValue49: type=DT_InM_stModeMng, value=1
    UInt8InitValue61
      value:
        integer literal UInt8InitValue61: type=DT_InM_tiRelax_pDsThrEstim, value=0
    UInt8InitValue73
      value:
        integer literal UInt8InitValue73: type=DT_InM_tiRelax_mTotEstim, value=0
    UInt8InitValue99
      value:
        integer literal UInt8InitValue99: type=DT_CanPurg_rOpCanPurgReq, value=0
  internal behavior IB_InMdlT: component=INMDLT
    data received event EV_InMdlT_013_DRE: mode-dependency=dependent-on-mode=[R_UCE_stWkuMainRelSt.RCD_stWkuMainRelSt.PreMainWakeUp, R_UCE_stWkuMainRelSt.RCD_stWkuMainRelSt.PostMainWakeUp, R_UCE_stWkuMainRelSt.RCD_stWkuMainRelSt.Invalid], start-on-event=RE_InMdlT_013_DRE, data=R_EV_InMdlT_013_DRE.EV_InMdlT_013_DRE
    mode switch event EV_InMdlT_044_MSE: start-on-event=RE_InMdlT_044_MSE, activation=ENTRY, mode=R_EcuM_CurrentMode.currentMode.RUN
    mode switch event EV_InMdlT_045_MSE: start-on-event=RE_InMdlT_045_MSE, activation=ENTRY, mode=R_EcuM_CurrentMode.currentMode.RUN
    mode switch event EV_InMdlT_042_MSE: start-on-event=RE_InMdlT_042_MSE, activation=ENTRY, mode=R_EcuM_CurrentMode.currentMode.RUN
    timing event EV_InMdlT_018_TEV: mode-dependency=dependent-on-mode=[R_UCE_stWkuMainRelSt.RCD_stWkuMainRelSt.PreMainWakeUp, R_UCE_stWkuMainRelSt.RCD_stWkuMainRelSt.PostMainWakeUp, R_UCE_stWkuMainRelSt.RCD_stWkuMainRelSt.Invalid], start-on-event=RE_InMdlT_018_TEV, period=0.005
    timing event EV_InMdlT_037_TEV: mode-dependency=dependent-on-mode=[R_UCE_stWkuMainRelSt.RCD_stWkuMainRelSt.PreMainWakeUp, R_UCE_stWkuMainRelSt.RCD_stWkuMainRelSt.PostMainWakeUp, R_UCE_stWkuMainRelSt.RCD_stWkuMainRelSt.Invalid], start-on-event=RE_InMdlT_037_TEV, period=0.005
    mode switch event EV_InMdlT_043_MSE: start-on-event=RE_InMdlT_043_MSE, activation=ENTRY, mode=R_EcuM_CurrentMode.currentMode.RUN
    4 x timing event, all with mode-dependency=dependent-on-mode=[R_UCE_stWkuMainRelSt.RCD_stWkuMainRelSt.PreMainWakeUp, R_UCE_stWkuMainRelSt.RCD_stWkuMainRelSt.PostMainWakeUp, R_UCE_stWkuMainRelSt.RCD_stWkuMainRelSt.Invalid], period=0.005:
      EV_InMdlT_012_TEV: start-on-event=RE_InMdlT_012_TEV
      EV_InMdlT_027_TEV: start-on-event=RE_InMdlT_027_TEV
      EV_InMdlT_002_TEV: start-on-event=RE_InMdlT_002_TEV
      EV_InMdlT_034_TEV: start-on-event=RE_InMdlT_034_TEV
    mode switch event EV_InMdlT_037_MSE: start-on-event=RE_InMdlT_037_MSE, activation=ENTRY, mode=R_EcuM_CurrentMode.currentMode.RUN
    timing event EV_InMdlT_008_TEV: mode-dependency=dependent-on-mode=[R_UCE_stWkuMainRelSt.RCD_stWkuMainRelSt.PreMainWakeUp, R_UCE_stWkuMainRelSt.RCD_stWkuMainRelSt.PostMainWakeUp, R_UCE_stWkuMainRelSt.RCD_stWkuMainRelSt.Invalid], start-on-event=RE_InMdlT_008_TEV, period=0.005
    mode switch event EV_InMdlT_041_MSE: start-on-event=RE_InMdlT_041_MSE, activation=ENTRY, mode=R_EcuM_CurrentMode.currentMode.RUN
    mode switch event EV_InMdlT_036_MSE: start-on-event=RE_InMdlT_036_MSE, activation=ENTRY, mode=R_EcuM_CurrentMode.currentMode.RUN
    timing event EV_InMdlT_004_TEV: mode-dependency=dependent-on-mode=[R_UCE_stWkuMainRelSt.RCD_stWkuMainRelSt.PreMainWakeUp, R_UCE_stWkuMainRelSt.RCD_stWkuMainRelSt.PostMainWakeUp, R_UCE_stWkuMainRelSt.RCD_stWkuMainRelSt.Invalid], start-on-event=RE_InMdlT_004_TEV, period=0.005
    timing event EV_InMdlT_010_TEV: mode-dependency=dependent-on-mode=[R_UCE_stWkuMainRelSt.RCD_stWkuMainRelSt.PreMainWakeUp, R_UCE_stWkuMainRelSt.RCD_stWkuMainRelSt.PostMainWakeUp, R_UCE_stWkuMainRelSt.RCD_stWkuMainRelSt.Invalid], start-on-event=RE_InMdlT_010_TEV, period=0.005
    mode switch event EV_InMdlT_039_MSE: start-on-event=RE_InMdlT_039_MSE, activation=ENTRY, mode=R_EcuM_CurrentMode.currentMode.RUN
    timing event EV_InMdlT_020_TEV: mode-dependency=dependent-on-mode=[R_UCE_stWkuMainRelSt.RCD_stWkuMainRelSt.PreMainWakeUp, R_UCE_stWkuMainRelSt.RCD_stWkuMainRelSt.PostMainWakeUp, R_UCE_stWkuMainRelSt.RCD_stWkuMainRelSt.Invalid], start-on-event=RE_InMdlT_020_TEV, period=0.005
    data received event EV_InMdlT_024_DRE: mode-dependency=dependent-on-mode=[R_UCE_stWkuMainRelSt.RCD_stWkuMainRelSt.PreMainWakeUp, R_UCE_stWkuMainRelSt.RCD_stWkuMainRelSt.PostMainWakeUp, R_UCE_stWkuMainRelSt.RCD_stWkuMainRelSt.Invalid], start-on-event=RE_InMdlT_024_DRE, data=R_EV_InMdlT_024_DRE.EV_InMdlT_024_DRE
    data received event EV_InMdlT_015_DRE: mode-dependency=dependent-on-mode=[R_UCE_stWkuMainRelSt.RCD_stWkuMainRelSt.PreMainWakeUp, R_UCE_stWkuMainRelSt.RCD_stWkuMainRelSt.PostMainWakeUp, R_UCE_stWkuMainRelSt.RCD_stWkuMainRelSt.Invalid], start-on-event=RE_InMdlT_015_DRE, data=R_EV_InMdlT_015_DRE.EV_InMdlT_015_DRE
    timing event EV_InMdlT_032_TEV: mode-dependency=dependent-on-mode=[R_UCE_stWkuMainRelSt.RCD_stWkuMainRelSt.PreMainWakeUp, R_UCE_stWkuMainRelSt.RCD_stWkuMainRelSt.PostMainWakeUp, R_UCE_stWkuMainRelSt.RCD_stWkuMainRelSt.Invalid], start-on-event=RE_InMdlT_032_TEV, period=0.005
    mode switch event EV_InMdlT_040_MSE: start-on-event=RE_InMdlT_040_MSE, activation=ENTRY, mode=R_EcuM_CurrentMode.currentMode.RUN
    timing event EV_InMdlT_006_TEV: mode-dependency=dependent-on-mode=[R_UCE_stWkuMainRelSt.RCD_stWkuMainRelSt.PreMainWakeUp, R_UCE_stWkuMainRelSt.RCD_stWkuMainRelSt.PostMainWakeUp, R_UCE_stWkuMainRelSt.RCD_stWkuMainRelSt.Invalid], start-on-event=RE_InMdlT_006_TEV, period=0.005
    mode switch event EV_InMdlT_047_MSE: start-on-event=RE_InMdlT_047_MSE, activation=ENTRY, mode=R_EcuM_CurrentMode.currentMode.RUN
    timing event EV_InMdlT_029_TEV: mode-dependency=dependent-on-mode=[R_UCE_stWkuMainRelSt.RCD_stWkuMainRelSt.PreMainWakeUp, R_UCE_stWkuMainRelSt.RCD_stWkuMainRelSt.PostMainWakeUp, R_UCE_stWkuMainRelSt.RCD_stWkuMainRelSt.Invalid], start-on-event=RE_InMdlT_029_TEV, period=0.005
    timing event EV_InMdlT_022_TEV: mode-dependency=dependent-on-mode=[R_UCE_stWkuMainRelSt.RCD_stWkuMainRelSt.PreMainWakeUp, R_UCE_stWkuMainRelSt.RCD_stWkuMainRelSt.PostMainWakeUp, R_UCE_stWkuMainRelSt.RCD_stWkuMainRelSt.Invalid], start-on-event=RE_InMdlT_022_TEV, period=0.005
    mode switch event EV_InMdlT_001_MSE: start-on-event=RE_InMdlT_001_MSE, activation=ENTRY, mode=R_EcuM_CurrentMode.currentMode.RUN
    timing event EV_InMdlT_033_TEV: mode-dependency=dependent-on-mode=[R_UCE_stWkuMainRelSt.RCD_stWkuMainRelSt.PreMainWakeUp, R_UCE_stWkuMainRelSt.RCD_stWkuMainRelSt.PostMainWakeUp, R_UCE_stWkuMainRelSt.RCD_stWkuMainRelSt.Invalid], start-on-event=RE_InMdlT_033_TEV, period=0.005
    mode switch event EV_InMdlT_035_MSE: start-on-event=RE_InMdlT_035_MSE, activation=ENTRY, mode=R_EcuM_CurrentMode.currentMode.RUN
    mode switch event EV_InMdlT_046_MSE: start-on-event=RE_InMdlT_046_MSE, activation=ENTRY, mode=R_EcuM_CurrentMode.currentMode.RUN
    4 x timing event, all with mode-dependency=dependent-on-mode=[R_UCE_stWkuMainRelSt.RCD_stWkuMainRelSt.PreMainWakeUp, R_UCE_stWkuMainRelSt.RCD_stWkuMainRelSt.PostMainWakeUp, R_UCE_stWkuMainRelSt.RCD_stWkuMainRelSt.Invalid], period=0.005:
      EV_InMdlT_031_TEV: start-on-event=RE_InMdlT_031_TEV
      EV_InMdlT_014_TEV: start-on-event=RE_InMdlT_014_TEV
      EV_InMdlT_026_TEV: start-on-event=RE_InMdlT_026_TEV
      EV_InMdlT_028_TEV: start-on-event=RE_InMdlT_028_TEV
    mode switch event EV_InMdlT_038_MSE: start-on-event=RE_InMdlT_038_MSE, activation=ENTRY, mode=R_EcuM_CurrentMode.currentMode.RUN
    timing event EV_InMdlT_016_TEV: mode-dependency=dependent-on-mode=[R_UCE_stWkuMainRelSt.RCD_stWkuMainRelSt.PreMainWakeUp, R_UCE_stWkuMainRelSt.RCD_stWkuMainRelSt.PostMainWakeUp, R_UCE_stWkuMainRelSt.RCD_stWkuMainRelSt.Invalid], start-on-event=RE_InMdlT_016_TEV, period=0.005
    43 x inter runnable variable, all with sw-calibration-access=READ-WRITE, communication-approach=EXPLICIT:
      InM_pDsThrSenEstim_irv: type=DT_InM_pDsThrSenEstim_irv, init-value=InitValue_Float32_0313
      InM_mFuStmEstim_irv: type=DT_InM_mFuStmEstim_irv, init-value=InitValue_Float32_0255
      InM_mfTotExEstim_irv: type=DT_InM_mfTotExEstim_irv, init-value=InitValue_UInt16_0301
      InM_pPrevSenBuffer_04_irv: type=DT_InM_pPrevSenBuffer_04_irv, init-value=InitValue_Float32_0315
      InM_concAirPredInCyl_irv: type=DT_InM_concAirPredInCyl_irv, init-value=InitValue_Float32_0261
      InM_nEngPred_irv: type=DT_InM_nEngPred_irv, init-value=InitValue_UInt16_0
      InM_cntPrevSenPres_irv: type=DT_InM_cntPrevSenPres_irv, init-value=InitValue_UInt8_0
      InM_mGradAirEstim_irv: type=DT_InM_mGradAirEstim_irv, init-value=InitValue_Float32_0265
      InM_mGradEGREstim_irv: type=DT_InM_mGradEGREstim_irv, init-value=InitValue_Float32_0279
      InM_concAirEstim_irv: type=DT_InM_concAirEstim_irv, init-value=InitValue_Float32_0249
      InM_pDsThrEstimPrev_irv: type=DT_InM_pDsThrEstimPrev_irv, init-value=InitValue_Float32_0285
      InM_concAirRaw_irv: type=DT_InM_concAirRaw_irv, init-value=InitValue_Float32_0317
      InM_concAirPred_irv: type=DT_InM_concAirPred_irv, init-value=InitValue_Float32_0267
      AirEfc_facChrExpScvFilEstim_irv: type=DT_AirEfc_facChrExpScvFilEstim_irv, init-value=InitValue_Float32_0247
      InM_ctEGRVlvCls_irv: type=DT_InM_ctEGRVlvCls_irv, init-value=InitValue_UInt32_0319
      FRT_tiSenFilTmr_irv: type=DT_FRT_tiSenFilTmr_irv, init-value=InitValue_UInt32_0
      InM_mTotEstim_irv: type=DT_InM_mTotEstim_irv, init-value=InitValue_Float32_0299
      InM_pPrevSenBuffer_01_irv: type=DT_InM_pPrevSenBuffer_01_irv, init-value=InitValue_Float32_0
      InM_tiHrznPredInCyl_irv: type=DT_InM_tiHrznPredInCyl_irv, init-value=InitValue_Float32_0281
      InM_facSlopEfcEstim_irv: type=DT_InM_facSlopEfcEstim_irv, init-value=InitValue_Float32_0287
      InM_pDsThrEstimLoResl_irv: type=DT_InM_pDsThrEstimLoResl_irv, init-value=InitValue_Float32_0297
      InM_pPrevSenFil_irv: type=DT_InM_pPrevSenFil_irv, init-value=InitValue_Float32_0291
      InM_tiHrznPred_facVlvOvlp_irv: type=DT_InM_tiHrznPred_facVlvOvlp_irv, init-value=InitValue_Float32_0263
      InM_tiHrznPred_irv: type=DT_InM_tiHrznPred_irv, init-value=InitValue_Float32_0303
      InM_pDsThrPredInCylRaw_irv: type=DT_InM_pDsThrPredInCylRaw_irv, init-value=InitValue_Float32_0273
      InM_mfFuStmCanPurgEstim_irv: type=DT_InM_mfFuStmCanPurgEstim_irv, init-value=InitValue_Float32_0245
      InM_concFuPredInCyl_irv: type=DT_InM_concFuPredInCyl_irv, init-value=InitValue_Float32_0253
      InM_pPrevSenBuffer_03_irv: type=DT_InM_pPrevSenBuffer_03_irv, init-value=InitValue_Float32_0257
      InM_pGradDsThrEstim_irv: type=DT_InM_pGradDsThrEstim_irv, init-value=InitValue_Float32_0289
      InM_agCkClsInVlvEstimRef2_irv: type=DT_InM_agCkClsInVlvEstimRef2_irv, init-value=InitValue_Float32_0251
      InM_pPrev1SenFil_irv: type=DT_InM_pPrev1SenFil_irv, init-value=InitValue_Float32_0295
      InM_mGradFuStmEstim_irv: type=DT_InM_mGradFuStmEstim_irv, init-value=InitValue_Float32_0243
      InM_pPrevSenBuffer_02_irv: type=DT_InM_pPrevSenBuffer_02_irv, init-value=InitValue_Float32_0283
      InM_pDsThr_facVlvOvlp_irv: type=DT_InM_pDsThr_facVlvOvlp_irv, init-value=InitValue_Float32_0307
      InM_mEGREstimPrev_irv: type=DT_InM_mEGREstimPrev_irv, init-value=InitValue_Float32_0271
      InM_mAirEstimPrev_irv: type=DT_InM_mAirEstimPrev_irv, init-value=InitValue_Float32_0269
      InM_concFuStmRaw_irv: type=DT_InM_concFuStmRaw_irv, init-value=InitValue_Float32_0305
      InM_mFuStmEstimPrev_irv: type=DT_InM_mFuStmEstimPrev_irv, init-value=InitValue_Float32_0277
      InM_concFuStmEstim_irv: type=DT_InM_concFuStmEstim_irv, init-value=InitValue_Float32_0275
      InM_concFuPred_irv: type=DT_InM_concFuPred_irv, init-value=InitValue_Float32_0293
      AirEfc_facChrExpFilEstim_irv: type=DT_AirEfc_facChrExpFilEstim_irv, init-value=InitValue_Float32_0259
      InM_pDsThrPredRaw_irv: type=DT_InM_pDsThrPredRaw_irv, init-value=InitValue_Float32_0309
      InM_pPrevSenSat_irv: type=DT_InM_pPrevSenSat_irv, init-value=InitValue_Float32_0311
    37 x runnable:
      RE_InMdlT_013_DRE: written-variable=[InM_ctEGRVlvCls_irv, InM_mEGREstimPrev_irv]
        data receive point dr_EV_InMdlT_013_DRE: data-element=R_EV_InMdlT_013_DRE.EV_InMdlT_013_DRE
        data send point ds_InM_mEGREstim: data-element=P_InM_mEGREstim.InM_mEGREstim
        data send point ds_InM_mEGREstimLoResl: data-element=P_InM_mEGREstimLoResl.InM_mEGREstimLoResl
      RE_InMdlT_043_MSE: read-variable=[InM_concFuStmRaw_irv, InM_concAirRaw_irv]
        data receive point dr_UsThrM_pDsThrMesCor: data-element=R_UsThrM_pDsThrMesCor.UsThrM_pDsThrMesCor
        data receive point dr_Ext_nEng: data-element=R_Ext_nEng.Ext_nEng
        18 x data send point:
          ds_InM_concFuPredInCylCor: data-element=P_InM_concFuPredInCylCor.InM_concFuPredInCylCor
          ds_InM_prm_concAirPredCyl: data-element=P_InM_prm_concAirPredCyl.InM_prm_concAirPredCyl
          ds_InM_concFuCor: data-element=P_InM_concFuCor.InM_concFuCor
          ds_InM_stModeMng: data-element=P_InM_stModeMng.InM_stModeMng
          ds_InM_nEngCor: data-element=P_InM_nEngCor.InM_nEngCor
          ds_InM_prm_concFuPredCyl: data-element=P_InM_prm_concFuPredCyl.InM_prm_concFuPredCyl
          ds_InM_prm_pDsThrPredOvlpCyl: data-element=P_InM_prm_pDsThrPredOvlpCyl.InM_prm_pDsThrPredOvlpCyl
          ds_InM_concAirCor: data-element=P_InM_concAirCor.InM_concAirCor
          ds_InM_pDsThrEstimErr: data-element=P_InM_pDsThrEstimErr.InM_pDsThrEstimErr
          ds_InM_prm_pDsThrPredCyl: data-element=P_InM_prm_pDsThrPredCyl.InM_prm_pDsThrPredCyl
          ds_InM_pDsThrPred: data-element=P_InM_pDsThrPred.InM_pDsThrPred
          ds_InM_concAirPredInCylCor: data-element=P_InM_concAirPredInCylCor.InM_concAirPredInCylCor
          ds_InM_concFuPredCor: data-element=P_InM_concFuPredCor.InM_concFuPredCor
          ds_InM_pDsThrCor: data-element=P_InM_pDsThrCor.InM_pDsThrCor
          ds_InM_pDsThrPredInCyl: data-element=P_InM_pDsThrPredInCyl.InM_pDsThrPredInCyl
          ds_InM_pDsThrPred_facVlvOvlp: data-element=P_InM_pDsThrPred_facVlvOvlp.InM_pDsThrPred_facVlvOvlp
          ds_InM_concAirPredCor: data-element=P_InM_concAirPredCor.InM_concAirPredCor
          ds_InM_pDynCorPres: data-element=P_InM_pDynCorPres.InM_pDynCorPres
      RE_InMdlT_027_TEV: written-variable=InM_mfFuStmCanPurgEstim_irv
        4 x data receive point:
          dr_Eng_stEru: data-element=R_Eng_stEru.Eng_stEru
          dr_CanPurg_concFuStmErr: data-element=R_CanPurg_concFuStmErr.CanPurg_concFuStmErr
          dr_CanPurg_concFuStmEstim: data-element=R_CanPurg_concFuStmEstim.CanPurg_concFuStmEstim
          dr_InM_mfTotCanPurgEstim: data-element=R_InM_mfTotCanPurgEstim.InM_mfTotCanPurgEstim
        data send point ds_InM_mfAirCanPurgEstim: data-element=P_InM_mfAirCanPurgEstim.InM_mfAirCanPurgEstim
      RE_InMdlT_016_TEV: read-variable=[InM_agCkClsInVlvEstimRef2_irv, InM_tiHrznPred_irv], written-variable=[InM_agCkClsInVlvEstimRef2_irv, InM_tiHrznPred_irv]
        5 x data receive point:
          dr_Ext_tiHldPerEng: data-element=R_Ext_tiHldPerEng.Ext_tiHldPerEng
          dr_Ext_agCkPosnCurRef2: data-element=R_Ext_agCkPosnCurRef2.Ext_agCkPosnCurRef2
          dr_Eng_stEru: data-element=R_Eng_stEru.Eng_stEru
          dr_Ext_agCkOpInVlvEstimRef0: data-element=R_Ext_agCkOpInVlvEstimRef0.Ext_agCkOpInVlvEstimRef0
          dr_Eng_noExCyl: data-element=R_Eng_noExCyl.Eng_noExCyl
      RE_InMdlT_029_TEV
        9 x data receive point:
          dr_AFA_rCor_arEffEGRVlv: data-element=R_AFA_rCor_arEffEGRVlv.AFA_rCor_arEffEGRVlv
          dr_InM_pDsThrCor: data-element=R_InM_pDsThrCor.InM_pDsThrCor
          dr_UsThrM_pUsThrCor: data-element=R_UsThrM_pUsThrCor.UsThrM_pUsThrCor
          dr_InM_pDsThrEstim: data-element=R_InM_pDsThrEstim.InM_pDsThrEstim
          dr_InThM_tSqrtEgUsEGRVlv: data-element=R_InThM_tSqrtEgUsEGRVlv.InThM_tSqrtEgUsEGRVlv
          dr_AFA_arEffEGRVlvOfs: data-element=R_AFA_arEffEGRVlvOfs.AFA_arEffEGRVlvOfs
          dr_InM_pBackEgPUsEGRVlv: data-element=R_InM_pBackEgPUsEGRVlv.InM_pBackEgPUsEGRVlv
          dr_EGRVlv_rOpEGRReq: data-element=R_EGRVlv_rOpEGRReq.EGRVlv_rOpEGRReq
          dr_ExM_mfEgWoutEGR: data-element=R_ExM_mfEgWoutEGR.ExM_mfEgWoutEGR
        6 x data send point:
          ds_InM_mfEGREstimEGRVlv: data-element=P_InM_mfEGREstimEGRVlv.InM_mfEGREstimEGRVlv
          ds_InM_pUsEGRVlv: data-element=P_InM_pUsEGRVlv.InM_pUsEGRVlv
          ds_InM_pBackEgPUsEGRVlv: data-element=P_InM_pBackEgPUsEGRVlv.InM_pBackEgPUsEGRVlv
          ds_InM_arEffAdpEGRVlv: data-element=P_InM_arEffAdpEGRVlv.InM_arEffAdpEGRVlv
          ds_InM_arEffEGRVlv: data-element=P_InM_arEffEGRVlv.InM_arEffEGRVlv
          ds_InM_mfEGRReq_arEGR: data-element=P_InM_mfEGRReq_arEGR.InM_mfEGRReq_arEGR
        sync call ssp_FRM_bInhInMDynCor: operation=R_FRM_bInhInMDynCor.GetFunctionPermission
        sync call ssp_FRM_bInhInMNomMod: operation=R_FRM_bInhInMNomMod.GetFunctionPermission
      RE_InMdlT_022_TEV: read-variable=[InM_pDsThrEstimLoResl_irv, InM_pPrevSenBuffer_04_irv, InM_pPrevSenSat_irv, InM_pPrevSenBuffer_03_irv, InM_pPrevSenBuffer_01_irv, InM_pDsThrSenEstim_irv, InM_pPrevSenFil_irv, InM_cntPrevSenPres_irv, InM_pPrevSenBuffer_02_irv], written-variable=[InM_pPrevSenBuffer_04_irv, InM_pPrevSenSat_irv, InM_pPrevSenBuffer_03_irv, InM_pPrevSenBuffer_01_irv, InM_pDsThrSenEstim_irv, InM_pPrevSenFil_irv, InM_cntPrevSenPres_irv, InM_pPrev1SenFil_irv, InM_pPrevSenBuffer_02_irv]
        data receive point dr_Eng_stEru: data-element=R_Eng_stEru.Eng_stEru
      RE_InMdlT_032_TEV
        7 x data receive point:
          dr_InM_mfEGREstimEGRVlv: data-element=R_InM_mfEGREstimEGRVlv.InM_mfEGREstimEGRVlv
          dr_Eng_stEru: data-element=R_Eng_stEru.Eng_stEru
          dr_InM_mfAirThrEstim: data-element=R_InM_mfAirThrEstim.InM_mfAirThrEstim
          dr_Blby_mfFuStmCmpAirSys: data-element=R_Blby_mfFuStmCmpAirSys.Blby_mfFuStmCmpAirSys
          dr_EngM_mfTotExCor: data-element=R_EngM_mfTotExCor.EngM_mfTotExCor
          dr_InM_rCohMnfMf: data-element=R_InM_rCohMnfMf.InM_rCohMnfMf
          dr_InM_mfTotCanPurgEstim: data-element=R_InM_mfTotCanPurgEstim.InM_mfTotCanPurgEstim
        data send point ds_InM_rCohMnfMf: data-element=P_InM_rCohMnfMf.InM_rCohMnfMf
      RE_InMdlT_033_TEV: read-variable=InM_tiHrznPred_facVlvOvlp_irv, written-variable=InM_tiHrznPred_facVlvOvlp_irv
        6 x data receive point:
          dr_Eng_noExCyl: data-element=R_Eng_noExCyl.Eng_noExCyl
          dr_Eng_stEru: data-element=R_Eng_stEru.Eng_stEru
          dr_Ext_agCkPosnCurRef2: data-element=R_Ext_agCkPosnCurRef2.Ext_agCkPosnCurRef2
          dr_Ext_agCkOpInVlvEstimRef0: data-element=R_Ext_agCkOpInVlvEstimRef0.Ext_agCkOpInVlvEstimRef0
          dr_Ext_agCkClsExVlvEstimRef0: data-element=R_Ext_agCkClsExVlvEstimRef0.Ext_agCkClsExVlvEstimRef0
          dr_Ext_tiHldPerEng: data-element=R_Ext_tiHldPerEng.Ext_tiHldPerEng
      RE_InMdlT_035_MSE
        data send point ds_InM_stTranLd: data-element=P_InM_stTranLd.InM_stTranLd
        data send point ds_InM_bAcceEng: data-element=P_InM_bAcceEng.InM_bAcceEng
        data send point ds_InM_mfAirDifIn: data-element=P_InM_mfAirDifIn.InM_mfAirDifIn
      RE_InMdlT_018_TEV: read-variable=[InM_tiHrznPred_irv, InM_tiHrznPredInCyl_irv, InM_nEngPred_irv, InM_mEGREstimPrev_irv, InM_mFuStmEstimPrev_irv, InM_concAirPred_irv, InM_tiHrznPred_facVlvOvlp_irv, InM_mTotEstim_irv, InM_pDsThr_facVlvOvlp_irv, InM_concAirPredInCyl_irv, InM_mGradEGREstim_irv, InM_pDsThrPredRaw_irv, InM_mAirEstimPrev_irv, InM_concFuPredInCyl_irv, InM_concAirEstim_irv, InM_pDsThrPredInCylRaw_irv, InM_mFuStmEstim_irv, InM_mGradFuStmEstim_irv, InM_pDsThrEstimLoResl_irv, InM_concFuStmEstim_irv, InM_concFuPred_irv, InM_mGradAirEstim_irv, InM_pDsThrEstimPrev_irv, InM_pGradDsThrEstim_irv], written-variable=[InM_nEngPred_irv, InM_concAirPred_irv, InM_pDsThr_facVlvOvlp_irv, InM_concAirPredInCyl_irv, InM_pDsThrPredRaw_irv, InM_concFuPredInCyl_irv, InM_pDsThrPredInCylRaw_irv, InM_concFuPred_irv]
        10 x data receive point:
          dr_InM_tiInvEigVal_pDsThr: data-element=R_InM_tiInvEigVal_pDsThr.InM_tiInvEigVal_pDsThr
          dr_InM_facCoplMassPres: data-element=R_InM_facCoplMassPres.InM_facCoplMassPres
          dr_InM_mAirEstim: data-element=R_InM_mAirEstim.InM_mAirEstim
          dr_Eng_stEru: data-element=R_Eng_stEru.Eng_stEru
          dr_InThM_tMixtInMnf: data-element=R_InThM_tMixtInMnf.InThM_tMixtInMnf
          dr_Ext_nEng: data-element=R_Ext_nEng.Ext_nEng
          dr_InM_mEGREstim: data-element=R_InM_mEGREstim.InM_mEGREstim
          dr_InM_tiInvEigVal_mAir: data-element=R_InM_tiInvEigVal_mAir.InM_tiInvEigVal_mAir
          dr_InM_rAirPres: data-element=R_InM_rAirPres.InM_rAirPres
          dr_UsThrM_pUsThrCor: data-element=R_UsThrM_pUsThrCor.UsThrM_pUsThrCor
      RE_InMdlT_044_MSE: read-variable=InM_pDsThrEstimLoResl_irv, written-variable=[InM_cntPrevSenPres_irv, InM_pPrevSenBuffer_03_irv, InM_pPrevSenBuffer_04_irv, InM_pPrevSenSat_irv, InM_pPrevSenFil_irv, InM_pPrevSenBuffer_01_irv, InM_pPrevSenBuffer_02_irv, InM_pPrev1SenFil_irv]
      RE_InMdlT_045_MSE
        6 x data send point:
          ds_InM_arEffAdpEGRVlv: data-element=P_InM_arEffAdpEGRVlv.InM_arEffAdpEGRVlv
          ds_InM_mfEGREstimEGRVlv: data-element=P_InM_mfEGREstimEGRVlv.InM_mfEGREstimEGRVlv
          ds_InM_arEffEGRVlv: data-element=P_InM_arEffEGRVlv.InM_arEffEGRVlv
          ds_InM_mfEGRReq_arEGR: data-element=P_InM_mfEGRReq_arEGR.InM_mfEGRReq_arEGR
          ds_InM_pUsEGRVlv: data-element=P_InM_pUsEGRVlv.InM_pUsEGRVlv
          ds_InM_pBackEgPUsEGRVlv: data-element=P_InM_pBackEgPUsEGRVlv.InM_pBackEgPUsEGRVlv
      RE_InMdlT_046_MSE: written-variable=[InM_ctEGRVlvCls_irv, InM_mEGREstimPrev_irv]
        data send point ds_InM_mEGREstim: data-element=P_InM_mEGREstim.InM_mEGREstim
        data send point ds_InM_mEGREstimLoResl: data-element=P_InM_mEGREstimLoResl.InM_mEGREstimLoResl
      RE_InMdlT_031_TEV
        6 x data receive point:
          dr_CanPurg_rOpCanPurgReq: data-element=R_CanPurg_rOpCanPurgReq.CanPurg_rOpCanPurgReq
          dr_UsThrM_tSqrtInAir: data-element=R_UsThrM_tSqrtInAir.UsThrM_tSqrtInAir
          dr_CanPurg_concFuStmEstim: data-element=R_CanPurg_concFuStmEstim.CanPurg_concFuStmEstim
          dr_UsThrM_pAirExt: data-element=R_UsThrM_pAirExt.UsThrM_pAirExt
          dr_Eng_stEru: data-element=R_Eng_stEru.Eng_stEru
          dr_InM_pDsThrEstim: data-element=R_InM_pDsThrEstim.InM_pDsThrEstim
        data send point ds_InM_mfTotCanPurgEstim: data-element=P_InM_mfTotCanPurgEstim.InM_mfTotCanPurgEstim
        data send point ds_InM_facCfeCanPurgCor: data-element=P_InM_facCfeCanPurgCor.InM_facCfeCanPurgCor
        sync call ssp_FRM_bInhInMDynCor: operation=R_FRM_bInhInMDynCor.GetFunctionPermission
      RE_InMdlT_028_TEV: read-variable=[InM_mfFuStmCanPurgEstim_irv, InM_concFuStmEstim_irv, InM_mFuStmEstim_irv, InM_mfTotExEstim_irv], written-variable=[InM_mGradFuStmEstim_irv, InM_mFuStmEstimPrev_irv, InM_mFuStmEstim_irv]
        5 x data receive point:
          dr_InM_bAcceEng: data-element=R_InM_bAcceEng.InM_bAcceEng
          dr_InM_tiRelax_mTotEstim: data-element=R_InM_tiRelax_mTotEstim.InM_tiRelax_mTotEstim
          dr_CanPurg_bAcvClsPurgReq: data-element=R_CanPurg_bAcvClsPurgReq.CanPurg_bAcvClsPurgReq
          dr_Blby_mfFuStmCmpAirSys: data-element=R_Blby_mfFuStmCmpAirSys.Blby_mfFuStmCmpAirSys
          dr_Eng_stEru: data-element=R_Eng_stEru.Eng_stEru
      RE_InMdlT_002_TEV: read-variable=InM_mfTotExEstim_irv
        4 x data receive point:
          dr_Eng_stEru: data-element=R_Eng_stEru.Eng_stEru
          dr_InM_mfAirThrEstim: data-element=R_InM_mfAirThrEstim.InM_mfAirThrEstim
          dr_InM_mfAirCanPurgEstim: data-element=R_InM_mfAirCanPurgEstim.InM_mfAirCanPurgEstim
          dr_InM_mfAirEstim: data-element=R_InM_mfAirEstim.InM_mfAirEstim
        data send point ds_InM_stTranLd: data-element=P_InM_stTranLd.InM_stTranLd
        data send point ds_InM_mfAirDifIn: data-element=P_InM_mfAirDifIn.InM_mfAirDifIn
        data send point ds_InM_bAcceEng: data-element=P_InM_bAcceEng.InM_bAcceEng
      RE_InMdlT_010_TEV: read-variable=[InM_pGradDsThrEstim_irv, InM_mFuStmEstim_irv], written-variable=[InM_mGradAirEstim_irv, InM_mAirEstimPrev_irv]
        17 x data receive point:
          dr_InThM_tMixtInMnf: data-element=R_InThM_tMixtInMnf.InThM_tMixtInMnf
          dr_InM_mfAirCanPurgEstim: data-element=R_InM_mfAirCanPurgEstim.InM_mfAirCanPurgEstim
          dr_InM_facRelaxCplMassPresEstim: data-element=R_InM_facRelaxCplMassPresEstim.InM_facRelaxCplMassPresEstim
          dr_InM_mEGREstim: data-element=R_InM_mEGREstim.InM_mEGREstim
          dr_InM_mfAirEstim: data-element=R_InM_mfAirEstim.InM_mfAirEstim
          dr_Eng_stEru: data-element=R_Eng_stEru.Eng_stEru
          dr_InM_mfEGREstimEGRVlv: data-element=R_InM_mfEGREstimEGRVlv.InM_mfEGREstimEGRVlv
          dr_InM_mfAirThrEstim: data-element=R_InM_mfAirThrEstim.InM_mfAirThrEstim
          dr_Ext_nEng: data-element=R_Ext_nEng.Ext_nEng
          dr_InM_tiRelax_mTotEstim: data-element=R_InM_tiRelax_mTotEstim.InM_tiRelax_mTotEstim
          dr_EGRVlv_bClnEGRFoul: data-element=R_EGRVlv_bClnEGRFoul.EGRVlv_bClnEGRFoul
          dr_InM_bAcceEng: data-element=R_InM_bAcceEng.InM_bAcceEng
          dr_UsThrM_pDsThrMesCor: data-element=R_UsThrM_pDsThrMesCor.UsThrM_pDsThrMesCor
          dr_UsThrM_tThrMes: data-element=R_UsThrM_tThrMes.UsThrM_tThrMes
          dr_InM_rAirPres: data-element=R_InM_rAirPres.InM_rAirPres
          dr_InM_pDsThrEstim: data-element=R_InM_pDsThrEstim.InM_pDsThrEstim
          dr_InM_mAirEstim: data-element=R_InM_mAirEstim.InM_mAirEstim
        data send point ds_InM_mAirEstim: data-element=P_InM_mAirEstim.InM_mAirEstim
      RE_InMdlT_015_DRE: written-variable=[InM_concAirRaw_irv, InM_concAirEstim_irv, InM_concFuStmEstim_irv, InM_concFuStmRaw_irv]
        data receive point dr_EV_InMdlT_015_DRE: data-element=R_EV_InMdlT_015_DRE.EV_InMdlT_015_DRE
        data send point ds_InM_concEGREstim: data-element=P_InM_concEGREstim.InM_concEGREstim
      RE_InMdlT_038_MSE: written-variable=InM_mfFuStmCanPurgEstim_irv
        data send point ds_InM_mfAirCanPurgEstim: data-element=P_InM_mfAirCanPurgEstim.InM_mfAirCanPurgEstim
      RE_InMdlT_012_TEV: read-variable=[InM_mEGREstimPrev_irv, InM_mGradEGREstim_irv, InM_ctEGRVlvCls_irv, InM_mfTotExEstim_irv], written-variable=[InM_mEGREstimPrev_irv, InM_mGradEGREstim_irv, InM_ctEGRVlvCls_irv]
        9 x data receive point:
          dr_EGRVlv_bAcvClsEGRReq: data-element=R_EGRVlv_bAcvClsEGRReq.EGRVlv_bAcvClsEGRReq
          dr_InM_mEGREstim: data-element=R_InM_mEGREstim.InM_mEGREstim
          dr_InM_mEGREstimLoResl: data-element=R_InM_mEGREstimLoResl.InM_mEGREstimLoResl
          dr_InM_concEGREstim: data-element=R_InM_concEGREstim.InM_concEGREstim
          dr_InM_tiRelax_mTotEstim: data-element=R_InM_tiRelax_mTotEstim.InM_tiRelax_mTotEstim
          dr_InM_mfEGREstimEGRVlv: data-element=R_InM_mfEGREstimEGRVlv.InM_mfEGREstimEGRVlv
          dr_Eng_stEru: data-element=R_Eng_stEru.Eng_stEru
          dr_EGRVlv_bClnEGRFoul: data-element=R_EGRVlv_bClnEGRFoul.EGRVlv_bClnEGRFoul
          dr_InM_bAcceEng: data-element=R_InM_bAcceEng.InM_bAcceEng
        data send point ds_InM_mEGREstimLoResl: data-element=P_InM_mEGREstimLoResl.InM_mEGREstimLoResl
      RE_InMdlT_026_TEV: read-variable=[InM_tiHrznPredInCyl_irv, InM_agCkClsInVlvEstimRef2_irv], written-variable=InM_tiHrznPredInCyl_irv
        4 x data receive point:
          dr_Ext_tiHldPerEng: data-element=R_Ext_tiHldPerEng.Ext_tiHldPerEng
          dr_Ext_agCkPosnCurRef2: data-element=R_Ext_agCkPosnCurRef2.Ext_agCkPosnCurRef2
          dr_Eng_stEru: data-element=R_Eng_stEru.Eng_stEru
          dr_Eng_noInCyl: data-element=R_Eng_noInCyl.Eng_noInCyl
      RE_InMdlT_006_TEV: read-variable=[InM_facSlopEfcEstim_irv, InM_mfTotExEstim_irv], written-variable=[InM_pGradDsThrEstim_irv, InM_pDsThrEstimLoResl_irv, InM_pDsThrEstimPrev_irv]
        22 x data receive point:
          dr_InM_facCfeGradThr: data-element=R_InM_facCfeGradThr.InM_facCfeGradThr
          dr_EGRVlv_bClnEGRFoul: data-element=R_EGRVlv_bClnEGRFoul.EGRVlv_bClnEGRFoul
          dr_InThM_tWallInMnf: data-element=R_InThM_tWallInMnf.InThM_tWallInMnf
          dr_UsThrM_pUsThrCor: data-element=R_UsThrM_pUsThrCor.UsThrM_pUsThrCor
          dr_UsThrM_pDsThrMesCor: data-element=R_UsThrM_pDsThrMesCor.UsThrM_pDsThrMesCor
          dr_UsThrM_tThrMes: data-element=R_UsThrM_tThrMes.UsThrM_tThrMes
          dr_InThM_facHeatExcWallInMnf: data-element=R_InThM_facHeatExcWallInMnf.InThM_facHeatExcWallInMnf
          dr_InM_mfAirThrEstim: data-element=R_InM_mfAirThrEstim.InM_mfAirThrEstim
          dr_InThM_tMixtInMnf: data-element=R_InThM_tMixtInMnf.InThM_tMixtInMnf
          dr_InM_mfTotCanPurgEstim: data-element=R_InM_mfTotCanPurgEstim.InM_mfTotCanPurgEstim
          dr_InM_bAcceEng: data-element=R_InM_bAcceEng.InM_bAcceEng
          dr_Eng_tOilEstim: data-element=R_Eng_tOilEstim.Eng_tOilEstim
          dr_Blby_mfFuStmCmpAirSys: data-element=R_Blby_mfFuStmCmpAirSys.Blby_mfFuStmCmpAirSys
          dr_InThM_tEGRInMnf: data-element=R_InThM_tEGRInMnf.InThM_tEGRInMnf
          dr_InM_mfEGREstimEGRVlv: data-element=R_InM_mfEGREstimEGRVlv.InM_mfEGREstimEGRVlv
          dr_InThM_tAirUsInVlvEstim: data-element=R_InThM_tAirUsInVlvEstim.InThM_tAirUsInVlvEstim
          dr_UsThrM_tSqrtInAir: data-element=R_UsThrM_tSqrtInAir.UsThrM_tSqrtInAir
          dr_InThM_tInMnfEstim: data-element=R_InThM_tInMnfEstim.InThM_tInMnfEstim
          dr_InM_pDsThrEstim: data-element=R_InM_pDsThrEstim.InM_pDsThrEstim
          dr_InM_arEffAdpThr: data-element=R_InM_arEffAdpThr.InM_arEffAdpThr
          dr_Ext_nEng: data-element=R_Ext_nEng.Ext_nEng
          dr_Eng_stEru: data-element=R_Eng_stEru.Eng_stEru
        data send point ds_InM_tiRelax_pDsThrEstim: data-element=P_InM_tiRelax_pDsThrEstim.InM_tiRelax_pDsThrEstim
        data send point ds_InM_tiInvEigVal_pDsThr: data-element=P_InM_tiInvEigVal_pDsThr.InM_tiInvEigVal_pDsThr
      RE_InMdlT_041_MSE: written-variable=[InM_mAirEstimPrev_irv, InM_mGradAirEstim_irv]
        data receive point dr_UsThrM_pDsThrMesCor: data-element=R_UsThrM_pDsThrMesCor.UsThrM_pDsThrMesCor
        data receive point dr_UsThrM_tThrMes: data-element=R_UsThrM_tThrMes.UsThrM_tThrMes
        data send point ds_InM_mAirEstim: data-element=P_InM_mAirEstim.InM_mAirEstim
      RE_InMdlT_037_TEV: written-variable=FRT_tiSenFilTmr_irv
      RE_InMdlT_024_DRE: read-variable=[InM_pPrevSenBuffer_01_irv, InM_pDsThrSenEstim_irv, InM_pPrevSenBuffer_03_irv, InM_pPrevSenFil_irv, InM_pPrev1SenFil_irv, FRT_tiSenFilTmr_irv, InM_pPrevSenBuffer_04_irv, InM_pPrevSenBuffer_02_irv, InM_cntPrevSenPres_irv], written-variable=[InM_pPrevSenBuffer_01_irv, InM_pDsThrSenEstim_irv, InM_pPrevSenBuffer_03_irv, InM_pPrevSenBuffer_04_irv, InM_pPrevSenBuffer_02_irv, InM_cntPrevSenPres_irv]
        data receive point dr_EV_InMdlT_024_DRE: data-element=R_EV_InMdlT_024_DRE.EV_InMdlT_024_DRE
        data receive point dr_Eng_stEru: data-element=R_Eng_stEru.Eng_stEru
        sync call ssp_GetTimer100usU32: operation=R_InMdlT_GetTimer_100us_U32.GetTimer_100us_U32
      RE_InMdlT_014_TEV: read-variable=[InM_concAirRaw_irv, InM_mFuStmEstim_irv, InM_concFuStmEstim_irv, InM_concFuStmRaw_irv, InM_mfFuStmCanPurgEstim_irv, InM_concAirEstim_irv], written-variable=[InM_mTotEstim_irv, InM_concAirRaw_irv, InM_concFuStmEstim_irv, InM_concFuStmRaw_irv, InM_concAirEstim_irv]
        7 x data receive point:
          dr_EGRVlv_bClnEGRFoul: data-element=R_EGRVlv_bClnEGRFoul.EGRVlv_bClnEGRFoul
          dr_Eng_stEru: data-element=R_Eng_stEru.Eng_stEru
          dr_InM_mAirEstim: data-element=R_InM_mAirEstim.InM_mAirEstim
          dr_InM_mEGREstim: data-element=R_InM_mEGREstim.InM_mEGREstim
          dr_EngM_mfTotExCor: data-element=R_EngM_mfTotExCor.EngM_mfTotExCor
          dr_Blby_mfFuStmCmpAirSys: data-element=R_Blby_mfFuStmCmpAirSys.Blby_mfFuStmCmpAirSys
          dr_InM_mfEGREstimEGRVlv: data-element=R_InM_mfEGREstimEGRVlv.InM_mfEGREstimEGRVlv
        data send point ds_InM_concEGREstim: data-element=P_InM_concEGREstim.InM_concEGREstim
      RE_InMdlT_037_MSE: written-variable=[AirEfc_facChrExpScvFilEstim_irv, InM_mfTotExEstim_irv, InM_facSlopEfcEstim_irv, AirEfc_facChrExpFilEstim_irv]
        data send point ds_InM_rTotLdExEstim: data-element=P_InM_rTotLdExEstim.InM_rTotLdExEstim
        data send point ds_InM_mfAirEstim: data-element=P_InM_mfAirEstim.InM_mfAirEstim
      RE_InMdlT_039_MSE
        data send point ds_InM_mfTotCanPurgEstim: data-element=P_InM_mfTotCanPurgEstim.InM_mfTotCanPurgEstim
        data send point ds_InM_facCfeCanPurgCor: data-element=P_InM_facCfeCanPurgCor.InM_facCfeCanPurgCor
      RE_InMdlT_034_TEV
        9 x data receive point:
          dr_InM_bAcceEng: data-element=R_InM_bAcceEng.InM_bAcceEng
          dr_InM_mfAirEstim: data-element=R_InM_mfAirEstim.InM_mfAirEstim
          dr_UsThrM_tSqrtInAir: data-element=R_UsThrM_tSqrtInAir.UsThrM_tSqrtInAir
          dr_InM_facCfeGradThr: data-element=R_InM_facCfeGradThr.InM_facCfeGradThr
          dr_Eng_stEru: data-element=R_Eng_stEru.Eng_stEru
          dr_InM_tiInvEigVal_pDsThr: data-element=R_InM_tiInvEigVal_pDsThr.InM_tiInvEigVal_pDsThr
          dr_InM_mAirEstim: data-element=R_InM_mAirEstim.InM_mAirEstim
          dr_InM_arEffAdpThr: data-element=R_InM_arEffAdpThr.InM_arEffAdpThr
          dr_InM_tiRelax_pDsThrEstim: data-element=R_InM_tiRelax_pDsThrEstim.InM_tiRelax_pDsThrEstim
        4 x data send point:
          ds_InM_facCoplMassPres: data-element=P_InM_facCoplMassPres.InM_facCoplMassPres
          ds_InM_tiRelax_mTotEstim: data-element=P_InM_tiRelax_mTotEstim.InM_tiRelax_mTotEstim
          ds_InM_facRelaxCplMassPresEstim: data-element=P_InM_facRelaxCplMassPresEstim.InM_facRelaxCplMassPresEstim
          ds_InM_tiInvEigVal_mAir: data-element=P_InM_tiInvEigVal_mAir.InM_tiInvEigVal_mAir
      RE_InMdlT_042_MSE: written-variable=[InM_mFuStmEstimPrev_irv, InM_mGradFuStmEstim_irv, InM_mFuStmEstim_irv]
      RE_InMdlT_004_TEV: read-variable=[InM_concAirEstim_irv, AirEfc_facChrExpFilEstim_irv, AirEfc_facChrExpScvFilEstim_irv], written-variable=[AirEfc_facChrExpFilEstim_irv, InM_mfTotExEstim_irv, AirEfc_facChrExpScvFilEstim_irv, InM_facSlopEfcEstim_irv]
        23 x data receive point:
          dr_InThM_tAirUsInVlvEstim: data-element=R_InThM_tAirUsInVlvEstim.InThM_tAirUsInVlvEstim
          dr_InM_prm_pDsThrPredOvlpCyl: data-element=R_InM_prm_pDsThrPredOvlpCyl.InM_prm_pDsThrPredOvlpCyl
          dr_ExM_prm_tExMnfEstimCyl: data-element=R_ExM_prm_tExMnfEstimCyl.ExM_prm_tExMnfEstimCyl
          dr_InjSys_prm_mFuInjH2ReqCyl: data-element=R_InjSys_prm_mFuInjH2ReqCyl.InjSys_prm_mFuInjH2ReqCyl
          dr_InjSys_prm_agEndInjH1ReqCyl: data-element=R_InjSys_prm_agEndInjH1ReqCyl.InjSys_prm_agEndInjH1ReqCyl
          dr_FuSysM_tFu: data-element=R_FuSysM_tFu.FuSysM_tFu
          dr_Ext_tCoMes: data-element=R_Ext_tCoMes.Ext_tCoMes
          dr_EngM_facCorOfsEfc: data-element=R_EngM_facCorOfsEfc.EngM_facCorOfsEfc
          dr_EngM_agCkOpInVlvEstimRef1: data-element=R_EngM_agCkOpInVlvEstimRef1.EngM_agCkOpInVlvEstimRef1
          dr_InjSys_prm_agBegInjH2ReqCyl: data-element=R_InjSys_prm_agBegInjH2ReqCyl.InjSys_prm_agBegInjH2ReqCyl
          dr_InjSys_prm_agEndInjH2ReqCyl: data-element=R_InjSys_prm_agEndInjH2ReqCyl.InjSys_prm_agEndInjH2ReqCyl
          dr_EngM_agCkClsExVlvEstimRef1: data-element=R_EngM_agCkClsExVlvEstimRef1.EngM_agCkClsExVlvEstimRef1
          dr_FARSp_rMixtCylSp: data-element=R_FARSp_rMixtCylSp.FARSp_rMixtCylSp
          dr_InjSys_prm_agBegInjH1ReqCyl: data-element=R_InjSys_prm_agBegInjH1ReqCyl.InjSys_prm_agBegInjH1ReqCyl
          dr_UsThrM_pAirExt: data-element=R_UsThrM_pAirExt.UsThrM_pAirExt
          dr_EngM_agCkClsInVlvEstimRef1: data-element=R_EngM_agCkClsInVlvEstimRef1.EngM_agCkClsInVlvEstimRef1
          dr_InM_pDsThrEstim: data-element=R_InM_pDsThrEstim.InM_pDsThrEstim
          dr_InjSys_prm_mFuInjH1ReqCyl: data-element=R_InjSys_prm_mFuInjH1ReqCyl.InjSys_prm_mFuInjH1ReqCyl
          dr_Eng_noInCyl: data-element=R_Eng_noInCyl.Eng_noInCyl
          dr_EngM_facCorSlopEfc: data-element=R_EngM_facCorSlopEfc.EngM_facCorSlopEfc
          dr_Ext_nEng: data-element=R_Ext_nEng.Ext_nEng
          dr_ExM_prm_pExMnfEstimOvlpCyl: data-element=R_ExM_prm_pExMnfEstimOvlpCyl.ExM_prm_pExMnfEstimOvlpCyl
          dr_InThM_nEngCor: data-element=R_InThM_nEngCor.InThM_nEngCor
        data send point ds_InM_mfAirEstim: data-element=P_InM_mfAirEstim.InM_mfAirEstim
        data send point ds_InM_rTotLdExEstim: data-element=P_InM_rTotLdExEstim.InM_rTotLdExEstim
        sync call ssp_LibEngCylPrm: operation=R_LibEngCylPrm.OP_LibEngCylPrm
        sync call ssp_LibAirEfc: operation=R_LibAirEfc.OP_LibAirEfc
      RE_InMdlT_020_TEV: read-variable=[InM_concFuPredInCyl_irv, InM_concAirPred_irv, InM_concFuStmEstim_irv, InM_concFuPred_irv, InM_concAirRaw_irv, InM_concFuStmRaw_irv, InM_pDsThrPredInCylRaw_irv, InM_pDsThrPredRaw_irv, InM_concAirEstim_irv, InM_pDsThr_facVlvOvlp_irv, InM_concAirPredInCyl_irv, InM_pDsThrSenEstim_irv, InM_nEngPred_irv]
        12 x data receive point:
          DRP_R_InM_prm_concAirPredCyl_InM_prm_concAirPredCyl: data-element=R_InM_prm_concAirPredCyl.InM_prm_concAirPredCyl
          dr_Eng_stEru: data-element=R_Eng_stEru.Eng_stEru
          dr_InM_pDsThrEstim: data-element=R_InM_pDsThrEstim.InM_pDsThrEstim
          dr_Eng_noInCyl: data-element=R_Eng_noInCyl.Eng_noInCyl
          DRP_R_InM_prm_pDsThrPredCyl_InM_prm_pDsThrPredCyl: data-element=R_InM_prm_pDsThrPredCyl.InM_prm_pDsThrPredCyl
          dr_UsThrM_pDsThrMesCor: data-element=R_UsThrM_pDsThrMesCor.UsThrM_pDsThrMesCor
          dr_UsThrM_pUsThrCor: data-element=R_UsThrM_pUsThrCor.UsThrM_pUsThrCor
          dr_InM_prm_concFuPredCyl: data-element=R_InM_prm_concFuPredCyl.InM_prm_concFuPredCyl
          dr_Ext_nEng: data-element=R_Ext_nEng.Ext_nEng
          dr_Eng_noExCyl: data-element=R_Eng_noExCyl.Eng_noExCyl
          DRP_R_InM_pDsThrEstimErr_InM_pDsThrEstimErr: data-element=R_InM_pDsThrEstimErr.InM_pDsThrEstimErr
          dr_Eng_noExNxtCyl: data-element=R_Eng_noExNxtCyl.Eng_noExNxtCyl
        18 x data send point:
          ds_InM_concFuPredInCylCor: data-element=P_InM_concFuPredInCylCor.InM_concFuPredInCylCor
          ds_InM_concAirPredCor: data-element=P_InM_concAirPredCor.InM_concAirPredCor
          ds_InM_prm_pDsThrPredOvlpCyl: data-element=P_InM_prm_pDsThrPredOvlpCyl.InM_prm_pDsThrPredOvlpCyl
          ds_InM_pDsThrEstimErr: data-element=P_InM_pDsThrEstimErr.InM_pDsThrEstimErr
          ds_InM_prm_pDsThrPredCyl: data-element=P_InM_prm_pDsThrPredCyl.InM_prm_pDsThrPredCyl
          ds_InM_nEngCor: data-element=P_InM_nEngCor.InM_nEngCor
          ds_InM_pDsThrPredInCyl: data-element=P_InM_pDsThrPredInCyl.InM_pDsThrPredInCyl
          ds_InM_pDsThrPred_facVlvOvlp: data-element=P_InM_pDsThrPred_facVlvOvlp.InM_pDsThrPred_facVlvOvlp
          ds_InM_prm_concFuPredCyl: data-element=P_InM_prm_concFuPredCyl.InM_prm_concFuPredCyl
          ds_InM_stModeMng: data-element=P_InM_stModeMng.InM_stModeMng
          ds_InM_concFuPredCor: data-element=P_InM_concFuPredCor.InM_concFuPredCor
          ds_InM_concAirPredInCylCor: data-element=P_InM_concAirPredInCylCor.InM_concAirPredInCylCor
          ds_InM_pDsThrPred: data-element=P_InM_pDsThrPred.InM_pDsThrPred
          ds_InM_pDynCorPres: data-element=P_InM_pDynCorPres.InM_pDynCorPres
          ds_InM_concFuCor: data-element=P_InM_concFuCor.InM_concFuCor
          ds_InM_pDsThrCor: data-element=P_InM_pDsThrCor.InM_pDsThrCor
          ds_InM_concAirCor: data-element=P_InM_concAirCor.InM_concAirCor
          ds_InM_prm_concAirPredCyl: data-element=P_InM_prm_concAirPredCyl.InM_prm_concAirPredCyl
        sync call ssp_FRM_bInhInMDynCor: operation=R_FRM_bInhInMDynCor.GetFunctionPermission
        sync call ssp_FRM_bInhInMNomMod: operation=R_FRM_bInhInMNomMod.GetFunctionPermission
      RE_InMdlT_040_MSE: written-variable=[InM_pDsThrEstimLoResl_irv, InM_pGradDsThrEstim_irv, InM_pDsThrEstimPrev_irv]
        data send point ds_InM_tiRelax_pDsThrEstim: data-element=P_InM_tiRelax_pDsThrEstim.InM_tiRelax_pDsThrEstim
        data send point ds_InM_tiInvEigVal_pDsThr: data-element=P_InM_tiInvEigVal_pDsThr.InM_tiInvEigVal_pDsThr
        data send point ds_InM_pDsThrEstim: data-element=P_InM_pDsThrEstim.InM_pDsThrEstim
      RE_InMdlT_008_TEV
        11 x data receive point:
          dr_UsThrM_pUsThrCor: data-element=R_UsThrM_pUsThrCor.UsThrM_pUsThrCor
          dr_AFA_facArEffThrOfs3: data-element=R_AFA_facArEffThrOfs3.AFA_facArEffThrOfs3
          dr_AFA_facArEffThrOfs1: data-element=R_AFA_facArEffThrOfs1.AFA_facArEffThrOfs1
          dr_InM_facCfeGradThr: data-element=R_InM_facCfeGradThr.InM_facCfeGradThr
          dr_InM_pDsThrEstim: data-element=R_InM_pDsThrEstim.InM_pDsThrEstim
          dr_InM_mfAirThrEstim: data-element=R_InM_mfAirThrEstim.InM_mfAirThrEstim
          dr_Eng_stEru: data-element=R_Eng_stEru.Eng_stEru
          dr_UsThrM_tSqrtInAir: data-element=R_UsThrM_tSqrtInAir.UsThrM_tSqrtInAir
          dr_ThrLrn_rOpSI: data-element=R_ThrLrn_rOpSI.ThrLrn_rOpSI
          dr_AFA_facArEffThrOfs2: data-element=R_AFA_facArEffThrOfs2.AFA_facArEffThrOfs2
          dr_AFA_arEffThrOfs: data-element=R_AFA_arEffThrOfs.AFA_arEffThrOfs
        4 x data send point:
          ds_InM_arEffAdpThr: data-element=P_InM_arEffAdpThr.InM_arEffAdpThr
          ds_InM_rAirPres: data-element=P_InM_rAirPres.InM_rAirPres
          DSP_P_InM_mfAirThrEstim_InM_mfAirThrEstim: data-element=P_InM_mfAirThrEstim.InM_mfAirThrEstim
          ds_InM_facCfeGradThr: data-element=P_InM_facCfeGradThr.InM_facCfeGradThr
      RE_InMdlT_036_MSE
        4 x data send point:
          ds_InM_facRelaxCplMassPresEstim: data-element=P_InM_facRelaxCplMassPresEstim.InM_facRelaxCplMassPresEstim
          ds_InM_tiRelax_mTotEstim: data-element=P_InM_tiRelax_mTotEstim.InM_tiRelax_mTotEstim
          ds_InM_tiInvEigVal_mAir: data-element=P_InM_tiInvEigVal_mAir.InM_tiInvEigVal_mAir
          ds_InM_facCoplMassPres: data-element=P_InM_facCoplMassPres.InM_facCoplMassPres
      RE_InMdlT_047_MSE: written-variable=[InM_concFuStmEstim_irv, InM_concAirRaw_irv, InM_concFuStmRaw_irv, InM_concAirEstim_irv]
        data send point ds_InM_concEGREstim: data-element=P_InM_concEGREstim.InM_concEGREstim
      RE_InMdlT_001_MSE: written-variable=[InM_mTotEstim_irv, InM_mGradEGREstim_irv, InM_nEngPred_irv, InM_tiHrznPred_facVlvOvlp_irv, InM_tiHrznPredInCyl_irv, InM_pDsThrSenEstim_irv, InM_pDsThrPredInCylRaw_irv, InM_concFuPred_irv, InM_pDsThr_facVlvOvlp_irv, InM_concAirPred_irv, InM_pDsThrPredRaw_irv, InM_concFuPredInCyl_irv, InM_tiHrznPred_irv, InM_agCkClsInVlvEstimRef2_irv, InM_concAirPredInCyl_irv]
        data send point ds_InM_rCohMnfMf: data-element=P_InM_rCohMnfMf.InM_rCohMnfMf
        data send point DSP_P_InM_mfAirThrEstim_InM_mfAirThrEstim: data-element=P_InM_mfAirThrEstim.InM_mfAirThrEstim
        data send point ds_InM_rAirPres: data-element=P_InM_rAirPres.InM_rAirPres
  swc implementation Imp_InMdlT: code-generator=Real-Time Workshop Embedded Coder 5.5 (R2010a) 25-Jan-2010, programming-language=C, behavior=IB_InMdlT
    code-descriptors:
      code CodeDescriptor: type=SRC
        10 x xfile:
          InMdlT_c: url=InMdlT.c
          InMdlT_Version_h: url=InMdlT_Version.h
          InMdlT_types_h: url=InMdlT_types.h
          InMdlT_private_h: url=InMdlT_private.h
          InMdlT_data_c: url=InMdlT_data.c
          InMdlT_MemMap_h: url=InMdlT_MemMap.h
          InMdlT_Def_c: url=InMdlT_Def.c
          InMdlT_Version_c: url=InMdlT_Version.c
          InMdlT_import_h: url=InMdlT_import.h
          InMdlT_h: url=InMdlT.h
package /Components/SWC_InMdlT/InMdlT_IRVDatatypes
  5 x integer type, all with lower-limit=0:
    DT_FRT_tiSenFilTmr_irv: base-type=uint32, upper-limit=4294967295
    DT_InM_cntPrevSenPres_irv: base-type=uint8, upper-limit=255
    DT_InM_ctEGRVlvCls_irv: base-type=uint32, upper-limit=4294967295
    DT_InM_mfTotExEstim_irv: base-type=uint16, upper-limit=65535
    DT_InM_nEngPred_irv: base-type=uint16, upper-limit=65535
  38 x real type, all with base-type=float32, allow-nan=false, encoding=SINGLE:
    DT_AirEfc_facChrExpFilEstim_irv
    DT_AirEfc_facChrExpScvFilEstim_irv
    DT_InM_agCkClsInVlvEstimRef2_irv
    DT_InM_concAirEstim_irv
    DT_InM_concAirPred_irv
    DT_InM_concAirPredInCyl_irv
    DT_InM_concAirRaw_irv
    DT_InM_concFuPred_irv
    DT_InM_concFuPredInCyl_irv
    DT_InM_concFuStmEstim_irv
    DT_InM_concFuStmRaw_irv
    DT_InM_facSlopEfcEstim_irv
    DT_InM_mAirEstimPrev_irv
    DT_InM_mEGREstimPrev_irv
    DT_InM_mfFuStmCanPurgEstim_irv
    DT_InM_mFuStmEstim_irv
    DT_InM_mFuStmEstimPrev_irv
    DT_InM_mGradAirEstim_irv
    DT_InM_mGradEGREstim_irv
    DT_InM_mGradFuStmEstim_irv
    DT_InM_mTotEstim_irv
    DT_InM_pDsThr_facVlvOvlp_irv
    DT_InM_pDsThrEstimLoResl_irv
    DT_InM_pDsThrEstimPrev_irv
    DT_InM_pDsThrPredInCylRaw_irv
    DT_InM_pDsThrPredRaw_irv
    DT_InM_pDsThrSenEstim_irv
    DT_InM_pGradDsThrEstim_irv
    DT_InM_pPrev1SenFil_irv
    DT_InM_pPrevSenBuffer_{01..04}_irv
    DT_InM_pPrevSenFil_irv
    DT_InM_pPrevSenSat_irv
    DT_InM_tiHrznPred_facVlvOvlp_irv
    DT_InM_tiHrznPred_irv
    DT_InM_tiHrznPredInCyl_irv
